AUTOSAR XML (schema 4-3-0)
package /CAN5/ISignalGroup
  11 x i signal group:
    CAN5_SG_FD_BCM1: i-signal=[CAN5_AllDoorSW, CAN5_AntiTheftSeatFold, CAN5_AntitheftSta, CAN5_BCM_Buzzer_Req, CAN5_BCM_DoorLock_Sta, CAN5_BrakeLamp, CAN5_CTDCtrl, CAN5_CTDLockSW, CAN5_CTDUnlockSW, CAN5_CrashDetd, CAN5_Dimmer, CAN5_DimmerEN, CAN5_DoorLockIND, CAN5_DrDoorSW, CAN5_Fr_ChargingDoorCtrl, CAN5_Fr_FogLamp, CAN5_Fr_Wiper_H, CAN5_Fr_Wiper_L, CAN5_H_Beam, CAN5_HazardSW, CAN5_HoodSW, CAN5_HornCtrl, CAN5_LBSD, CAN5_LDRL, CAN5_LTurnLP, CAN5_L_APM_WdwEnable, CAN5_L_Beam, CAN5_LockSetting, CAN5_MirrorCtrl, CAN5_MirrorDefog, CAN5_PosLamp, CAN5_PsDoorSW, CAN5_RBSD, CAN5_RDRL, CAN5_RLDoorSW, CAN5_RRDoorSW, CAN5_RTurnLP, CAN5_ReverseLamp, CAN5_RoomLampH, CAN5_RoomLampL, CAN5_Rr_ChargingDoorCtrl, CAN5_Rr_Defog, CAN5_Rr_FogLamp, CAN5_Rr_Wiper, CAN5_TailgateHDSW, CAN5_TailgateRemote, CAN5_Tailgate_SW, CAN5_TrunkRel, CAN5_WasherCtrl, CAN5_WiperFixMode], system-signal-group=CAN5_SG_FD_BCM1
    CAN5_SG_FD_CONN1: i-signal=[CAN5_CCU_AutoLampSts, CAN5_FD_DKC_VehData_Err, CAN5_FD_DKC_VehData_Sta, CAN5_FD_TBOX_DTCData_Err, CAN5_FD_TBOX_DTCData_Sta, CAN5_FD_TBOX_VehData_Err, CAN5_FD_TBOX_VehData_Sta, CAN5_SWC_mode_Sta], system-signal-group=CAN5_SG_FD_CONN1
    CAN5_SG_FD_THCM2: i-signal=[CAN5_ACSubMode, CAN5_APTC_ActFrRiPwr, CAN5_BatLoopActWtFlw, CAN5_CCU_CbnPreACWkSts, CAN5_CCU_CbnPreEstimdTi, CAN5_CCU_CbnPreSts, CAN5_CCU_HiVoltageReq, CAN5_CoolgFanActDuty, CAN5_DeiceModReq, CAN5_FD_Blower_Cmd, CAN5_FD_Comp_Cmd, CAN5_FD_EWP1_Cmd, CAN5_FD_EWP2_Cmd, CAN5_FD_EWP3_Cmd, CAN5_FD_EXV1_Cmd, CAN5_FD_EXV2_Cmd, CAN5_FD_FWV_Cmd, CAN5_FD_FrLeAPTCHeatPwr_Cmd, CAN5_FD_FrRiAPTCHeatPwr_Cmd, CAN5_FD_FrWPTCHeatPwr_Cmd, CAN5_FD_RrAPTCHeatPwr_Cmd, CAN5_FD_SOTXV_Cmd, CAN5_FD_SOV1_Cmd, CAN5_FD_SOV2_Cmd, CAN5_FD_SOV3_Cmd, CAN5_FD_TWV_Cmd], system-signal-group=CAN5_SG_FD_THCM2
    CAN5_SG_FD_VCU0: i-signal=[CAN5_EVCCAplusPwrUpReq, CAN5_FDADC12VDetAvg, CAN5_Fr_TqSource, CAN5_HVRlyOpFail, CAN5_HVTHCMSysAvail, CAN5_LVBattChrgtimeAct, CAN5_LVBattVoltSta, CAN5_LVChrgHoldTAct, CAN5_LVSilentChrgLv, CAN5_LVSilentChrgReq, CAN5_LVSilentChrgSta, CAN5_MCUActDisFail, CAN5_PMMAllowECUSleep, CAN5_PowerDownFault, CAN5_PowerDownState, CAN5_PowerUpFault, CAN5_PowerUpState, CAN5_PwrDownReq, CAN5_PwrStaConstraint, CAN5_PwrStaONTOIVIPopReq, CAN5_PwrStaONTOIVIPopT, CAN5_PwrStaSelect, CAN5_PwrStaTOSta, CAN5_PwrUpReq, CAN5_Rr_TqSource, CAN5_SchedChgTOSta, CAN5_SilentChkAllowSleep, CAN5_SysAllowReadySta, CAN5_SysPwrSta, CAN5_TCountSta, CAN5_TimerAllowSleep, CAN5_VCUBrkSWSta, CAN5_VCUFLDoorSta, CAN5_VCUFRDoorSta, CAN5_VCURLDoorSta, CAN5_VCURRDoorSta, CAN5_VehHVPwrAvail4THCM], system-signal-group=CAN5_SG_FD_VCU0
    CAN5_SG_FD_VCU1: i-signal=[CAN5_MSA_Crl_Sta, CAN5_PwrSta, CAN5_ShiftGearPosn], system-signal-group=CAN5_SG_FD_VCU1
    CAN5_SG_FD_VCU3: i-signal=[CAN5_CS_VCU3_CAN1, CAN5_EquivAccPedalSWSta, CAN5_Fr_EDUActTqValid, CAN5_Fr_EDUAvailBrkRgnTq, CAN5_Fr_EDUAvailBrkRgnTqValid, CAN5_Fr_EDURealARgnTq, CAN5_Fr_EDURealDrvOrBRgnTq, CAN5_Fr_EDURolRgnTqValid, CAN5_Fr_EDUSpd, CAN5_Fr_EDUSpdValid, CAN5_Fr_RgnDecrSta, CAN5_Fr_RgnPermSta, CAN5_PTCS_PermSta, CAN5_RC_VCU3_CAN1, CAN5_RgnAbnorSta, CAN5_Rr_EDUActTqValid, CAN5_Rr_EDUAvailBrkRgnTq, CAN5_Rr_EDUAvailBrkRgnTqValid, CAN5_Rr_EDURealARgnTq, CAN5_Rr_EDURealDrvOrBRgnTq, CAN5_Rr_EDURolRgnTqValid, CAN5_Rr_EDUSpd, CAN5_Rr_EDUSpdValid, CAN5_Rr_RgnDecrSta, CAN5_Rr_RgnPermSta], system-signal-group=CAN5_SG_FD_VCU3
    CAN5_SG_FD_VCU4: i-signal=[CAN5_Eng_AGSCloseSta, CAN5_Eng_ActvDmpDisabSta, CAN5_Eng_CoastDwSta, CAN5_Eng_PwrLockSta, CAN5_VehMalfunLevel], system-signal-group=CAN5_SG_FD_VCU4
    CAN5_SG_FD_VCU5: i-signal=[CAN5_EDriveSysErr_AccPedalErr, CAN5_EDriveSysErr_MCUErr, CAN5_EDriveSysErr_ShifterErr, CAN5_EDriveSysErr_VCUErr, CAN5_HVSysErr_IsolationErr, CAN5_HVSysErr_PackErr, CAN5_HVSysErr_RelayErr, CAN5_LVSysErr_PwrOutpErr, CAN5_LimphomeAct, CAN5_LowSOCWarn, CAN5_PwrStaErr, CAN5_Re_VehThdChkSta], system-signal-group=CAN5_SG_FD_VCU5
    CAN5_SG_TBOX1: i-signal=[CAN5_Antitheft_Zero, CAN5_CbnPreACEnaReq, CAN5_CbnPreReq, CAN5_CbnPreTarT, CAN5_PowerOff_T_Set, CAN5_ReOutsideMirror, CAN5_Re_DoorLock, CAN5_Re_PwrReqTbox, CAN5_Re_Radio, CAN5_Remote_ACTemp, CAN5_Remote_AutoReq, CAN5_Remote_MidAutoReq, CAN5_TBOX_NET_SIG_STR, CAN5_TBOX_Re_DTCData, CAN5_TBOX_Re_VehData, CAN5_TBOX_RemoteOn, CAN5_TBOX_Remote_PW, CAN5_TBOX_TEST_STATUS, CAN5_Uncounting_Req], system-signal-group=CAN5_SG_TBOX1
    CAN5_SG_XNMm_FUSION: i-signal=[CAN5_NM_FUSION_Active_WU, CAN5_NM_FUSION_CSB, CAN5_NM_FUSION_ERROR_State, CAN5_NM_FUSION_Node_ID, CAN5_NM_FUSION_PNI, CAN5_NM_FUSION_Rpt_Msg_Req], system-signal-group=CAN5_SG_XNMm_FUSION
    CAN5_SG_XNMm_TBOX: i-signal=[CAN5_NM_TBOX_Active_WU, CAN5_NM_TBOX_CSB, CAN5_NM_TBOX_ERROR_State, CAN5_NM_TBOX_Node_ID, CAN5_NM_TBOX_PNI, CAN5_NM_TBOX_Rpt_Msg_Req], system-signal-group=CAN5_SG_XNMm_TBOX
package /CAN5/Cluster
  can cluster CAN5: baudrate=500, can-fd-baudrate=2000
    can physical channel CAN5: comm-connectors=ConnCAN5
      frame CAN5_DiagFuncReqFT: id 0x7D0, frame-length=8, can-addressing-mode=STANDARD, can-fd-frame-support=true, can-frame-rx-behavior=CAN-FD, can-frame-tx-behavior=CAN-FD
        n pdu CAN5_DiagFuncReqFT: length=8
      frame CAN5_DiagPhysReqToTBOX: id 0x6D0, frame-length=8, can-addressing-mode=STANDARD, can-fd-frame-support=true, can-frame-rx-behavior=CAN-FD, can-frame-tx-behavior=CAN-FD
        n pdu CAN5_DiagPhysReqToTBOX: length=8
      frame CAN5_DiagRespFromTBOX: id 0x650, frame-length=8, can-addressing-mode=STANDARD, can-fd-frame-support=true, can-frame-rx-behavior=CAN-FD, can-frame-tx-behavior=CAN-FD
        n pdu CAN5_DiagRespFromTBOX: length=8
      frame CAN5_FD_BCM1: id 0x216, frame-length=16, can-addressing-mode=STANDARD, can-fd-frame-support=true, can-frame-rx-behavior=CAN-FD, can-frame-tx-behavior=CAN-FD
        pdu CAN5_FD_BCM1: length=16, minimum-delay=0.0, transmission-mode-true-timing={cyclic-timing=time-period=0.2, event-controlled-timing={number-of-repetitions=0, repetition-period=0.06}}, unused-bit-pattern=0
          mapping CAN5_SG_FD_BCM1: i-signal-group=CAN5_SG_FD_BCM1, start-position=0, transfer-property=TRIGGERED-ON-CHANGE
          signal CAN5_AllDoorSW: start 124, 1 bit, big-endian, i-signal-type=PRIMITIVE, init-value=constant-reference=Init_CAN5_AllDoorSW, base-type=uint8, implementation-data-type=uint8, transfer-property=TRIGGERED-ON-CHANGE
          signal CAN5_AntiTheftSeatFold: start 84, 1 bit, big-endian, i-signal-type=PRIMITIVE, init-value=constant-reference=Init_CAN5_AntiTheftSeatFold, base-type=uint8, implementation-data-type=uint8, transfer-property=TRIGGERED-ON-CHANGE
          signal CAN5_AntitheftSta: start 83, 2 bit, big-endian, i-signal-type=PRIMITIVE, init-value=constant-reference=Init_CAN5_AntitheftSta, base-type=uint8, implementation-data-type=uint8, transfer-property=TRIGGERED-ON-CHANGE
          signal CAN5_BCM_Buzzer_Req: start 64, 1 bit, big-endian, i-signal-type=PRIMITIVE, init-value=constant-reference=Init_CAN5_BCM_Buzzer_Req, base-type=uint8, implementation-data-type=uint8, transfer-property=TRIGGERED-ON-CHANGE
          signal CAN5_BCM_DoorLock_Sta: start 70, 1 bit, big-endian, i-signal-type=PRIMITIVE, init-value=constant-reference=Init_CAN5_BCM_DoorLock_Sta, base-type=uint8, implementation-data-type=uint8, transfer-property=TRIGGERED-ON-CHANGE
          signal CAN5_BrakeLamp: start 90, 1 bit, big-endian, i-signal-type=PRIMITIVE, init-value=constant-reference=Init_CAN5_BrakeLamp, base-type=uint8, implementation-data-type=uint8, transfer-property=TRIGGERED-ON-CHANGE
          signal CAN5_CTDCtrl: start 113, 2 bit, big-endian, i-signal-type=PRIMITIVE, init-value=constant-reference=Init_CAN5_CTDCtrl, base-type=uint8, implementation-data-type=uint8, transfer-property=TRIGGERED-ON-CHANGE
          signal CAN5_CTDLockSW: start 118, 1 bit, big-endian, i-signal-type=PRIMITIVE, init-value=constant-reference=Init_CAN5_CTDLockSW, base-type=uint8, implementation-data-type=uint8, transfer-property=TRIGGERED-ON-CHANGE
          signal CAN5_CTDUnlockSW: start 119, 1 bit, big-endian, i-signal-type=PRIMITIVE, init-value=constant-reference=Init_CAN5_CTDUnlockSW, base-type=uint8, implementation-data-type=uint8, transfer-property=TRIGGERED-ON-CHANGE
          signal CAN5_CrashDetd: start 85, 1 bit, big-endian, i-signal-type=PRIMITIVE, init-value=constant-reference=Init_CAN5_CrashDetd, base-type=uint8, implementation-data-type=uint8, transfer-property=TRIGGERED-ON-CHANGE
          signal CAN5_Dimmer: start 78, 7 bit, big-endian, i-signal-type=PRIMITIVE, init-value=constant-reference=Init_CAN5_Dimmer, base-type=uint8, implementation-data-type=uint8, transfer-property=TRIGGERED-ON-CHANGE
          signal CAN5_DimmerEN: start 69, 1 bit, big-endian, i-signal-type=PRIMITIVE, init-value=constant-reference=Init_CAN5_DimmerEN, base-type=uint8, implementation-data-type=uint8, transfer-property=TRIGGERED-ON-CHANGE
          signal CAN5_DoorLockIND: start 125, 1 bit, big-endian, i-signal-type=PRIMITIVE, init-value=constant-reference=Init_CAN5_DoorLockIND, base-type=uint8, implementation-data-type=uint8, transfer-property=TRIGGERED-ON-CHANGE
          signal CAN5_DrDoorSW: start 120, 1 bit, big-endian, i-signal-type=PRIMITIVE, init-value=constant-reference=Init_CAN5_DrDoorSW, base-type=uint8, implementation-data-type=uint8, transfer-property=TRIGGERED-ON-CHANGE
          signal CAN5_Fr_ChargingDoorCtrl: start 115, 2 bit, big-endian, i-signal-type=PRIMITIVE, init-value=constant-reference=Init_CAN5_Fr_ChargingDoorCtrl, base-type=uint8, implementation-data-type=uint8, transfer-property=TRIGGERED-ON-CHANGE
          signal CAN5_Fr_FogLamp: start 93, 1 bit, big-endian, i-signal-type=PRIMITIVE, init-value=constant-reference=Init_CAN5_Fr_FogLamp, base-type=uint8, implementation-data-type=uint8, transfer-property=TRIGGERED-ON-CHANGE
          signal CAN5_Fr_Wiper_H: start 110, 1 bit, big-endian, i-signal-type=PRIMITIVE, init-value=constant-reference=Init_CAN5_Fr_Wiper_H, base-type=uint8, implementation-data-type=uint8, transfer-property=TRIGGERED-ON-CHANGE
          signal CAN5_Fr_Wiper_L: start 111, 1 bit, big-endian, i-signal-type=PRIMITIVE, init-value=constant-reference=Init_CAN5_Fr_Wiper_L, base-type=uint8, implementation-data-type=uint8, transfer-property=TRIGGERED-ON-CHANGE
          signal CAN5_H_Beam: start 101, 1 bit, big-endian, i-signal-type=PRIMITIVE, init-value=constant-reference=Init_CAN5_H_Beam, base-type=uint8, implementation-data-type=uint8, transfer-property=TRIGGERED-ON-CHANGE
          signal CAN5_HazardSW: start 95, 1 bit, big-endian, i-signal-type=PRIMITIVE, init-value=constant-reference=Init_CAN5_HazardSW, base-type=uint8, implementation-data-type=uint8, transfer-property=TRIGGERED-ON-CHANGE
          signal CAN5_HoodSW: start 126, 1 bit, big-endian, i-signal-type=PRIMITIVE, init-value=constant-reference=Init_CAN5_HoodSW, base-type=uint8, implementation-data-type=uint8, transfer-property=TRIGGERED-ON-CHANGE
          signal CAN5_HornCtrl: start 71, 1 bit, big-endian, i-signal-type=PRIMITIVE, init-value=constant-reference=Init_CAN5_HornCtrl, base-type=uint8, implementation-data-type=uint8, transfer-property=TRIGGERED-ON-CHANGE
          signal CAN5_LBSD: start 91, 1 bit, big-endian, i-signal-type=PRIMITIVE, init-value=constant-reference=Init_CAN5_LBSD, base-type=uint8, implementation-data-type=uint8, transfer-property=TRIGGERED-ON-CHANGE
          signal CAN5_LDRL: start 103, 1 bit, big-endian, i-signal-type=PRIMITIVE, init-value=constant-reference=Init_CAN5_LDRL, base-type=uint8, implementation-data-type=uint8, transfer-property=TRIGGERED-ON-CHANGE
          signal CAN5_LTurnLP: start 80, 1 bit, big-endian, i-signal-type=PRIMITIVE, init-value=constant-reference=Init_CAN5_LTurnLP, base-type=uint8, implementation-data-type=uint8, transfer-property=TRIGGERED-ON-CHANGE
          signal CAN5_L_APM_WdwEnable: start 87, 1 bit, big-endian, i-signal-type=PRIMITIVE, init-value=constant-reference=Init_CAN5_L_APM_WdwEnable, base-type=uint8, implementation-data-type=uint8, transfer-property=TRIGGERED-ON-CHANGE
          signal CAN5_L_Beam: start 100, 1 bit, big-endian, i-signal-type=PRIMITIVE, init-value=constant-reference=Init_CAN5_L_Beam, base-type=uint8, implementation-data-type=uint8, transfer-property=TRIGGERED-ON-CHANGE
          signal CAN5_LockSetting: start 79, 1 bit, big-endian, i-signal-type=PRIMITIVE, init-value=constant-reference=Init_CAN5_LockSetting, base-type=uint8, implementation-data-type=uint8, transfer-property=TRIGGERED-ON-CHANGE
          signal CAN5_MirrorCtrl: start 109, 2 bit, big-endian, i-signal-type=PRIMITIVE, init-value=constant-reference=Init_CAN5_MirrorCtrl, base-type=uint8, implementation-data-type=uint8, transfer-property=TRIGGERED-ON-CHANGE
          signal CAN5_MirrorDefog: start 104, 1 bit, big-endian, i-signal-type=PRIMITIVE, init-value=constant-reference=Init_CAN5_MirrorDefog, base-type=uint8, implementation-data-type=uint8, transfer-property=TRIGGERED-ON-CHANGE
          signal CAN5_PosLamp: start 102, 1 bit, big-endian, i-signal-type=PRIMITIVE, init-value=constant-reference=Init_CAN5_PosLamp, base-type=uint8, implementation-data-type=uint8, transfer-property=TRIGGERED-ON-CHANGE
          signal CAN5_PsDoorSW: start 121, 1 bit, big-endian, i-signal-type=PRIMITIVE, init-value=constant-reference=Init_CAN5_PsDoorSW, base-type=uint8, implementation-data-type=uint8, transfer-property=TRIGGERED-ON-CHANGE
          signal CAN5_RBSD: start 92, 1 bit, big-endian, i-signal-type=PRIMITIVE, init-value=constant-reference=Init_CAN5_RBSD, base-type=uint8, implementation-data-type=uint8, transfer-property=TRIGGERED-ON-CHANGE
          signal CAN5_RDRL: start 88, 1 bit, big-endian, i-signal-type=PRIMITIVE, init-value=constant-reference=Init_CAN5_RDRL, base-type=uint8, implementation-data-type=uint8, transfer-property=TRIGGERED-ON-CHANGE
          signal CAN5_RLDoorSW: start 122, 1 bit, big-endian, i-signal-type=PRIMITIVE, init-value=constant-reference=Init_CAN5_RLDoorSW, base-type=uint8, implementation-data-type=uint8, transfer-property=TRIGGERED-ON-CHANGE
          signal CAN5_RRDoorSW: start 123, 1 bit, big-endian, i-signal-type=PRIMITIVE, init-value=constant-reference=Init_CAN5_RRDoorSW, base-type=uint8, implementation-data-type=uint8, transfer-property=TRIGGERED-ON-CHANGE
          signal CAN5_RTurnLP: start 81, 1 bit, big-endian, i-signal-type=PRIMITIVE, init-value=constant-reference=Init_CAN5_RTurnLP, base-type=uint8, implementation-data-type=uint8, transfer-property=TRIGGERED-ON-CHANGE
          signal CAN5_ReverseLamp: start 89, 1 bit, big-endian, i-signal-type=PRIMITIVE, init-value=constant-reference=Init_CAN5_ReverseLamp, base-type=uint8, implementation-data-type=uint8, transfer-property=TRIGGERED-ON-CHANGE
          signal CAN5_RoomLampH: start 68, 1 bit, big-endian, i-signal-type=PRIMITIVE, init-value=constant-reference=Init_CAN5_RoomLampH, base-type=uint8, implementation-data-type=uint8, transfer-property=TRIGGERED-ON-CHANGE
          signal CAN5_RoomLampL: start 67, 1 bit, big-endian, i-signal-type=PRIMITIVE, init-value=constant-reference=Init_CAN5_RoomLampL, base-type=uint8, implementation-data-type=uint8, transfer-property=TRIGGERED-ON-CHANGE
          signal CAN5_Rr_ChargingDoorCtrl: start 117, 2 bit, big-endian, i-signal-type=PRIMITIVE, init-value=constant-reference=Init_CAN5_Rr_ChargingDoorCtrl, base-type=uint8, implementation-data-type=uint8, transfer-property=TRIGGERED-ON-CHANGE
          signal CAN5_Rr_Defog: start 105, 1 bit, big-endian, i-signal-type=PRIMITIVE, init-value=constant-reference=Init_CAN5_Rr_Defog, base-type=uint8, implementation-data-type=uint8, transfer-property=TRIGGERED-ON-CHANGE
          signal CAN5_Rr_FogLamp: start 94, 1 bit, big-endian, i-signal-type=PRIMITIVE, init-value=constant-reference=Init_CAN5_Rr_FogLamp, base-type=uint8, implementation-data-type=uint8, transfer-property=TRIGGERED-ON-CHANGE
          signal CAN5_Rr_Wiper: start 96, 1 bit, big-endian, i-signal-type=PRIMITIVE, init-value=constant-reference=Init_CAN5_Rr_Wiper, base-type=uint8, implementation-data-type=uint8, transfer-property=TRIGGERED-ON-CHANGE
          signal CAN5_TailgateHDSW: start 107, 1 bit, big-endian, i-signal-type=PRIMITIVE, init-value=constant-reference=Init_CAN5_TailgateHDSW, base-type=uint8, implementation-data-type=uint8, transfer-property=TRIGGERED-ON-CHANGE
          signal CAN5_TailgateRemote: start 66, 2 bit, big-endian, i-signal-type=PRIMITIVE, init-value=constant-reference=Init_CAN5_TailgateRemote, base-type=uint8, implementation-data-type=uint8, transfer-property=TRIGGERED-ON-CHANGE
          signal CAN5_Tailgate_SW: start 127, 1 bit, big-endian, i-signal-type=PRIMITIVE, init-value=constant-reference=Init_CAN5_Tailgate_SW, base-type=uint8, implementation-data-type=uint8, transfer-property=TRIGGERED-ON-CHANGE
          signal CAN5_TrunkRel: start 106, 1 bit, big-endian, i-signal-type=PRIMITIVE, init-value=constant-reference=Init_CAN5_TrunkRel, base-type=uint8, implementation-data-type=uint8, transfer-property=TRIGGERED-ON-CHANGE
          signal CAN5_WasherCtrl: start 99, 2 bit, big-endian, i-signal-type=PRIMITIVE, init-value=constant-reference=Init_CAN5_WasherCtrl, base-type=uint8, implementation-data-type=uint8, transfer-property=TRIGGERED-ON-CHANGE
          signal CAN5_WiperFixMode: start 97, 1 bit, big-endian, i-signal-type=PRIMITIVE, init-value=constant-reference=Init_CAN5_WiperFixMode, base-type=uint8, implementation-data-type=uint8, transfer-property=TRIGGERED-ON-CHANGE
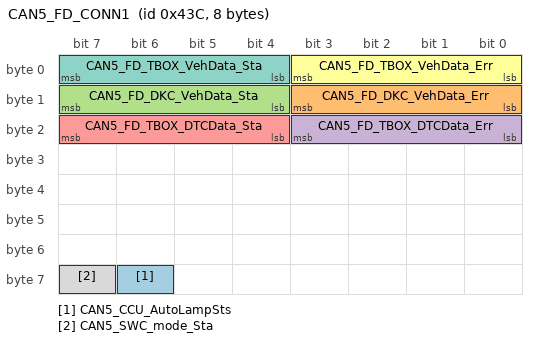
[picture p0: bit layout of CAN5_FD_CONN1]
      frame CAN5_FD_CONN1: id 0x43C, frame-length=8, can-addressing-mode=STANDARD, can-fd-frame-support=true, can-frame-rx-behavior=CAN-FD, can-frame-tx-behavior=CAN-FD
        pdu CAN5_FD_CONN1: length=8, minimum-delay=0.0, transmission-mode-true-timing={cyclic-timing=time-period=0.1, event-controlled-timing={number-of-repetitions=0, repetition-period=0.02}}, unused-bit-pattern=0
          mapping CAN5_SG_FD_CONN1: i-signal-group=CAN5_SG_FD_CONN1, start-position=0, transfer-property=TRIGGERED-ON-CHANGE
          signal CAN5_CCU_AutoLampSts: start 62, 1 bit, big-endian, i-signal-type=PRIMITIVE, init-value=constant-reference=Init_CAN5_CCU_AutoLampSts, base-type=uint8, implementation-data-type=uint8, transfer-property=PENDING
          signal CAN5_FD_DKC_VehData_Err: start 11, 4 bit, big-endian, i-signal-type=PRIMITIVE, init-value=constant-reference=Init_CAN5_FD_DKC_VehData_Err, base-type=uint8, implementation-data-type=uint8, transfer-property=TRIGGERED-ON-CHANGE
          signal CAN5_FD_DKC_VehData_Sta: start 15, 4 bit, big-endian, i-signal-type=PRIMITIVE, init-value=constant-reference=Init_CAN5_FD_DKC_VehData_Sta, base-type=uint8, implementation-data-type=uint8, transfer-property=TRIGGERED-ON-CHANGE
          signal CAN5_FD_TBOX_DTCData_Err: start 19, 4 bit, big-endian, i-signal-type=PRIMITIVE, init-value=constant-reference=Init_CAN5_FD_TBOX_DTCData_Err, base-type=uint8, implementation-data-type=uint8, transfer-property=TRIGGERED-ON-CHANGE
          signal CAN5_FD_TBOX_DTCData_Sta: start 23, 4 bit, big-endian, i-signal-type=PRIMITIVE, init-value=constant-reference=Init_CAN5_FD_TBOX_DTCData_Sta, base-type=uint8, implementation-data-type=uint8, transfer-property=TRIGGERED-ON-CHANGE
          signal CAN5_FD_TBOX_VehData_Err: start 3, 4 bit, big-endian, i-signal-type=PRIMITIVE, init-value=constant-reference=Init_CAN5_FD_TBOX_VehData_Err, base-type=uint8, implementation-data-type=uint8, transfer-property=TRIGGERED-ON-CHANGE
          signal CAN5_FD_TBOX_VehData_Sta: start 7, 4 bit, big-endian, i-signal-type=PRIMITIVE, init-value=constant-reference=Init_CAN5_FD_TBOX_VehData_Sta, base-type=uint8, implementation-data-type=uint8, transfer-property=TRIGGERED-ON-CHANGE
          signal CAN5_SWC_mode_Sta: start 63, 1 bit, big-endian, i-signal-type=PRIMITIVE, init-value=constant-reference=Init_CAN5_SWC_mode_Sta, base-type=uint8, implementation-data-type=uint8, transfer-property=TRIGGERED-ON-CHANGE
      frame CAN5_FD_THCM2: id 0x186, frame-length=20, can-addressing-mode=STANDARD, can-fd-frame-support=true, can-frame-rx-behavior=CAN-FD, can-frame-tx-behavior=CAN-FD
        pdu CAN5_FD_THCM2: length=20, minimum-delay=0.0, transmission-mode-true-timing={cyclic-timing=time-period=0.1, event-controlled-timing={number-of-repetitions=0, repetition-period=0.01}}, unused-bit-pattern=0
          mapping CAN5_SG_FD_THCM2: i-signal-group=CAN5_SG_FD_THCM2, start-position=0, transfer-property=TRIGGERED-ON-CHANGE
          signal CAN5_ACSubMode: start 11, 3 bit, big-endian, i-signal-type=PRIMITIVE, init-value=constant-reference=Init_CAN5_ACSubMode, base-type=uint8, implementation-data-type=uint8, transfer-property=PENDING
          signal CAN5_APTC_ActFrRiPwr: start 143, 8 bit, big-endian, i-signal-type=PRIMITIVE, init-value=constant-reference=Init_CAN5_APTC_ActFrRiPwr, base-type=uint8, implementation-data-type=uint8, transfer-property=TRIGGERED-ON-CHANGE
          signal CAN5_BatLoopActWtFlw: start 151, 8 bit, big-endian, i-signal-type=PRIMITIVE, init-value=constant-reference=Init_CAN5_BatLoopActWtFlw, base-type=uint8, implementation-data-type=uint8, transfer-property=PENDING
          signal CAN5_CCU_CbnPreACWkSts: start 35, 2 bit, big-endian, i-signal-type=PRIMITIVE, init-value=constant-reference=Init_CAN5_CCU_CbnPreACWkSts, base-type=uint8, implementation-data-type=uint8, transfer-property=PENDING
          signal CAN5_CCU_CbnPreEstimdTi: start 55, 6 bit, big-endian, i-signal-type=PRIMITIVE, init-value=constant-reference=Init_CAN5_CCU_CbnPreEstimdTi, base-type=uint8, implementation-data-type=uint8, transfer-property=PENDING
          signal CAN5_CCU_CbnPreSts: start 39, 2 bit, big-endian, i-signal-type=PRIMITIVE, init-value=constant-reference=Init_CAN5_CCU_CbnPreSts, base-type=uint8, implementation-data-type=uint8, transfer-property=PENDING
          signal CAN5_CCU_HiVoltageReq: start 23, 1 bit, big-endian, i-signal-type=PRIMITIVE, init-value=constant-reference=Init_CAN5_CCU_HiVoltageReq, base-type=uint8, implementation-data-type=uint8, transfer-property=PENDING
          signal CAN5_CoolgFanActDuty: start 159, 8 bit, big-endian, i-signal-type=PRIMITIVE, init-value=constant-reference=Init_CAN5_CoolgFanActDuty, base-type=uint8, implementation-data-type=uint8, transfer-property=TRIGGERED-ON-CHANGE
          signal CAN5_DeiceModReq: start 37, 2 bit, big-endian, i-signal-type=PRIMITIVE, init-value=constant-reference=Init_CAN5_DeiceModReq, base-type=uint8, implementation-data-type=uint8, transfer-property=PENDING
          signal CAN5_FD_Blower_Cmd: start 7, 8 bit, big-endian, i-signal-type=PRIMITIVE, init-value=constant-reference=Init_CAN5_FD_Blower_Cmd, base-type=uint8, implementation-data-type=uint8, transfer-property=TRIGGERED-ON-CHANGE
          signal CAN5_FD_Comp_Cmd: start 22, 15 bit, big-endian, i-signal-type=PRIMITIVE, init-value=constant-reference=Init_CAN5_FD_Comp_Cmd, base-type=uint16, implementation-data-type=uint16, transfer-property=TRIGGERED-ON-CHANGE
          signal CAN5_FD_EWP1_Cmd: start 135, 8 bit, big-endian, i-signal-type=PRIMITIVE, init-value=constant-reference=Init_CAN5_FD_EWP1_Cmd, base-type=uint8, implementation-data-type=uint8, transfer-property=PENDING
          signal CAN5_FD_EWP2_Cmd: start 127, 8 bit, big-endian, i-signal-type=PRIMITIVE, init-value=constant-reference=Init_CAN5_FD_EWP2_Cmd, base-type=uint8, implementation-data-type=uint8, transfer-property=PENDING
          signal CAN5_FD_EWP3_Cmd: start 119, 8 bit, big-endian, i-signal-type=PRIMITIVE, init-value=constant-reference=Init_CAN5_FD_EWP3_Cmd, base-type=uint8, implementation-data-type=uint8, transfer-property=PENDING
          signal CAN5_FD_EXV1_Cmd: start 33, 10 bit, big-endian, i-signal-type=PRIMITIVE, init-value=constant-reference=Init_CAN5_FD_EXV1_Cmd, base-type=uint16, implementation-data-type=uint16, transfer-property=PENDING
          signal CAN5_FD_EXV2_Cmd: start 49, 10 bit, big-endian, i-signal-type=PRIMITIVE, init-value=constant-reference=Init_CAN5_FD_EXV2_Cmd, base-type=uint16, implementation-data-type=uint16, transfer-property=PENDING
          signal CAN5_FD_FWV_Cmd: start 8, 1 bit, big-endian, i-signal-type=PRIMITIVE, init-value=constant-reference=Init_CAN5_FD_FWV_Cmd, base-type=uint8, implementation-data-type=uint8, transfer-property=PENDING
          signal CAN5_FD_FrLeAPTCHeatPwr_Cmd: start 87, 8 bit, big-endian, i-signal-type=PRIMITIVE, init-value=constant-reference=Init_CAN5_FD_FrLeAPTCHeatPwr_Cmd, base-type=uint8, implementation-data-type=uint8, transfer-property=TRIGGERED-ON-CHANGE
          signal CAN5_FD_FrRiAPTCHeatPwr_Cmd: start 79, 8 bit, big-endian, i-signal-type=PRIMITIVE, init-value=constant-reference=Init_CAN5_FD_FrRiAPTCHeatPwr_Cmd, base-type=uint8, implementation-data-type=uint8, transfer-property=TRIGGERED-ON-CHANGE
          signal CAN5_FD_FrWPTCHeatPwr_Cmd: start 103, 16 bit, big-endian, i-signal-type=PRIMITIVE, init-value=constant-reference=Init_CAN5_FD_FrWPTCHeatPwr_Cmd, base-type=uint16, implementation-data-type=uint16, transfer-property=TRIGGERED-ON-CHANGE
          signal CAN5_FD_RrAPTCHeatPwr_Cmd: start 95, 8 bit, big-endian, i-signal-type=PRIMITIVE, init-value=constant-reference=Init_CAN5_FD_RrAPTCHeatPwr_Cmd, base-type=uint8, implementation-data-type=uint8, transfer-property=TRIGGERED-ON-CHANGE
          signal CAN5_FD_SOTXV_Cmd: start 12, 1 bit, big-endian, i-signal-type=PRIMITIVE, init-value=constant-reference=Init_CAN5_FD_SOTXV_Cmd, base-type=uint8, implementation-data-type=uint8, transfer-property=PENDING
          signal CAN5_FD_SOV1_Cmd: start 13, 1 bit, big-endian, i-signal-type=PRIMITIVE, init-value=constant-reference=Init_CAN5_FD_SOV1_Cmd, base-type=uint8, implementation-data-type=uint8, transfer-property=PENDING
          signal CAN5_FD_SOV2_Cmd: start 14, 1 bit, big-endian, i-signal-type=PRIMITIVE, init-value=constant-reference=Init_CAN5_FD_SOV2_Cmd, base-type=uint8, implementation-data-type=uint8, transfer-property=PENDING
          signal CAN5_FD_SOV3_Cmd: start 15, 1 bit, big-endian, i-signal-type=PRIMITIVE, init-value=constant-reference=Init_CAN5_FD_SOV3_Cmd, base-type=uint8, implementation-data-type=uint8, transfer-property=PENDING
          signal CAN5_FD_TWV_Cmd: start 71, 8 bit, big-endian, i-signal-type=PRIMITIVE, init-value=constant-reference=Init_CAN5_FD_TWV_Cmd, base-type=uint8, implementation-data-type=uint8, transfer-property=PENDING
      frame CAN5_FD_VCU0: id 0x1F0, frame-length=16, can-addressing-mode=STANDARD, can-fd-frame-support=true, can-frame-rx-behavior=CAN-FD, can-frame-tx-behavior=CAN-FD
        pdu CAN5_FD_VCU0: length=16, minimum-delay=0.0, transmission-mode-true-timing={cyclic-timing=time-period=0.1, event-controlled-timing={number-of-repetitions=0, repetition-period=0.002}}, unused-bit-pattern=0
          mapping CAN5_SG_FD_VCU0: i-signal-group=CAN5_SG_FD_VCU0, start-position=0, transfer-property=TRIGGERED-ON-CHANGE
          signal CAN5_EVCCAplusPwrUpReq: start 94, 1 bit, big-endian, i-signal-type=PRIMITIVE, init-value=constant-reference=Init_CAN5_EVCCAplusPwrUpReq, base-type=uint8, implementation-data-type=uint8, transfer-property=TRIGGERED-ON-CHANGE
          signal CAN5_FDADC12VDetAvg: start 127, 8 bit, big-endian, i-signal-type=PRIMITIVE, init-value=constant-reference=Init_CAN5_FDADC12VDetAvg, base-type=uint8, implementation-data-type=uint8, transfer-property=TRIGGERED-ON-CHANGE
          signal CAN5_Fr_TqSource: start 47, 4 bit, big-endian, i-signal-type=PRIMITIVE, init-value=constant-reference=Init_CAN5_Fr_TqSource, base-type=uint8, implementation-data-type=uint8, transfer-property=TRIGGERED-ON-CHANGE
          signal CAN5_HVRlyOpFail: start 56, 1 bit, big-endian, i-signal-type=PRIMITIVE, init-value=constant-reference=Init_CAN5_HVRlyOpFail, base-type=uint8, implementation-data-type=uint8, transfer-property=TRIGGERED-ON-CHANGE
          signal CAN5_HVTHCMSysAvail: start 41, 2 bit, big-endian, i-signal-type=PRIMITIVE, init-value=constant-reference=Init_CAN5_HVTHCMSysAvail, base-type=uint8, implementation-data-type=uint8, transfer-property=TRIGGERED-ON-CHANGE
          signal CAN5_LVBattChrgtimeAct: start 107, 12 bit, big-endian, i-signal-type=PRIMITIVE, init-value=constant-reference=Init_CAN5_LVBattChrgtimeAct, base-type=uint16, implementation-data-type=uint16, transfer-property=TRIGGERED-ON-CHANGE
          signal CAN5_LVBattVoltSta: start 43, 2 bit, big-endian, i-signal-type=PRIMITIVE, init-value=constant-reference=Init_CAN5_LVBattVoltSta, base-type=uint8, implementation-data-type=uint8, transfer-property=TRIGGERED-ON-CHANGE
          signal CAN5_LVChrgHoldTAct: start 91, 12 bit, big-endian, i-signal-type=PRIMITIVE, init-value=constant-reference=Init_CAN5_LVChrgHoldTAct, base-type=uint16, implementation-data-type=uint16, transfer-property=TRIGGERED-ON-CHANGE
          signal CAN5_LVSilentChrgLv: start 83, 2 bit, big-endian, i-signal-type=PRIMITIVE, init-value=constant-reference=Init_CAN5_LVSilentChrgLv, base-type=uint8, implementation-data-type=uint8, transfer-property=TRIGGERED-ON-CHANGE
          signal CAN5_LVSilentChrgReq: start 81, 1 bit, big-endian, i-signal-type=PRIMITIVE, init-value=constant-reference=Init_CAN5_LVSilentChrgReq, base-type=uint8, implementation-data-type=uint8, transfer-property=TRIGGERED-ON-CHANGE
          signal CAN5_LVSilentChrgSta: start 85, 2 bit, big-endian, i-signal-type=PRIMITIVE, init-value=constant-reference=Init_CAN5_LVSilentChrgSta, base-type=uint8, implementation-data-type=uint8, transfer-property=TRIGGERED-ON-CHANGE
          signal CAN5_MCUActDisFail: start 71, 1 bit, big-endian, i-signal-type=PRIMITIVE, init-value=constant-reference=Init_CAN5_MCUActDisFail, base-type=uint8, implementation-data-type=uint8, transfer-property=TRIGGERED-ON-CHANGE
          signal CAN5_PMMAllowECUSleep: start 95, 1 bit, big-endian, i-signal-type=PRIMITIVE, init-value=constant-reference=Init_CAN5_PMMAllowECUSleep, base-type=uint8, implementation-data-type=uint8, transfer-property=TRIGGERED-ON-CHANGE
          signal CAN5_PowerDownFault: start 19, 4 bit, big-endian, i-signal-type=PRIMITIVE, init-value=constant-reference=Init_CAN5_PowerDownFault, base-type=uint8, implementation-data-type=uint8, transfer-property=TRIGGERED-ON-CHANGE
          signal CAN5_PowerDownState: start 22, 3 bit, big-endian, i-signal-type=PRIMITIVE, init-value=constant-reference=Init_CAN5_PowerDownState, base-type=uint8, implementation-data-type=uint8, transfer-property=TRIGGERED-ON-CHANGE
          signal CAN5_PowerUpFault: start 11, 4 bit, big-endian, i-signal-type=PRIMITIVE, init-value=constant-reference=Init_CAN5_PowerUpFault, base-type=uint8, implementation-data-type=uint8, transfer-property=TRIGGERED-ON-CHANGE
          signal CAN5_PowerUpState: start 15, 4 bit, big-endian, i-signal-type=PRIMITIVE, init-value=constant-reference=Init_CAN5_PowerUpState, base-type=uint8, implementation-data-type=uint8, transfer-property=TRIGGERED-ON-CHANGE
          signal CAN5_PwrDownReq: start 37, 2 bit, big-endian, i-signal-type=PRIMITIVE, init-value=constant-reference=Init_CAN5_PwrDownReq, base-type=uint8, implementation-data-type=uint8, transfer-property=TRIGGERED-ON-CHANGE
          signal CAN5_PwrStaConstraint: start 29, 3 bit, big-endian, i-signal-type=PRIMITIVE, init-value=constant-reference=Init_CAN5_PwrStaConstraint, base-type=uint8, implementation-data-type=uint8, transfer-property=TRIGGERED-ON-CHANGE
          signal CAN5_PwrStaONTOIVIPopReq: start 70, 1 bit, big-endian, i-signal-type=PRIMITIVE, init-value=constant-reference=Init_CAN5_PwrStaONTOIVIPopReq, base-type=uint8, implementation-data-type=uint8, transfer-property=TRIGGERED-ON-CHANGE
          signal CAN5_PwrStaONTOIVIPopT: start 67, 12 bit, big-endian, i-signal-type=PRIMITIVE, init-value=constant-reference=Init_CAN5_PwrStaONTOIVIPopT, base-type=uint16, implementation-data-type=uint16, transfer-property=TRIGGERED-ON-CHANGE
          signal CAN5_PwrStaSelect: start 31, 2 bit, big-endian, i-signal-type=PRIMITIVE, init-value=constant-reference=Init_CAN5_PwrStaSelect, base-type=uint8, implementation-data-type=uint8, transfer-property=TRIGGERED-ON-CHANGE
          signal CAN5_PwrStaTOSta: start 69, 1 bit, big-endian, i-signal-type=PRIMITIVE, init-value=constant-reference=Init_CAN5_PwrStaTOSta, base-type=uint8, implementation-data-type=uint8, transfer-property=TRIGGERED-ON-CHANGE
          signal CAN5_PwrUpReq: start 39, 2 bit, big-endian, i-signal-type=PRIMITIVE, init-value=constant-reference=Init_CAN5_PwrUpReq, base-type=uint8, implementation-data-type=uint8, transfer-property=TRIGGERED-ON-CHANGE
          signal CAN5_Rr_TqSource: start 35, 4 bit, big-endian, i-signal-type=PRIMITIVE, init-value=constant-reference=Init_CAN5_Rr_TqSource, base-type=uint8, implementation-data-type=uint8, transfer-property=TRIGGERED-ON-CHANGE
          signal CAN5_SchedChgTOSta: start 87, 1 bit, big-endian, i-signal-type=PRIMITIVE, init-value=constant-reference=Init_CAN5_SchedChgTOSta, base-type=uint8, implementation-data-type=uint8, transfer-property=TRIGGERED-ON-CHANGE
          signal CAN5_SilentChkAllowSleep: start 86, 1 bit, big-endian, i-signal-type=PRIMITIVE, init-value=constant-reference=Init_CAN5_SilentChkAllowSleep, base-type=uint8, implementation-data-type=uint8, transfer-property=TRIGGERED-ON-CHANGE
          signal CAN5_SysAllowReadySta: start 57, 1 bit, big-endian, i-signal-type=PRIMITIVE, init-value=constant-reference=Init_CAN5_SysAllowReadySta, base-type=uint8, implementation-data-type=uint8, transfer-property=TRIGGERED-ON-CHANGE
          signal CAN5_SysPwrSta: start 7, 4 bit, big-endian, i-signal-type=PRIMITIVE, init-value=constant-reference=Init_CAN5_SysPwrSta, base-type=uint8, implementation-data-type=uint8, transfer-property=TRIGGERED-ON-CHANGE
          signal CAN5_TCountSta: start 26, 2 bit, big-endian, i-signal-type=PRIMITIVE, init-value=constant-reference=Init_CAN5_TCountSta, base-type=uint8, implementation-data-type=uint8, transfer-property=TRIGGERED-ON-CHANGE
          signal CAN5_TimerAllowSleep: start 80, 1 bit, big-endian, i-signal-type=PRIMITIVE, init-value=constant-reference=Init_CAN5_TimerAllowSleep, base-type=uint8, implementation-data-type=uint8, transfer-property=TRIGGERED-ON-CHANGE
          signal CAN5_VCUBrkSWSta: start 63, 2 bit, big-endian, i-signal-type=PRIMITIVE, init-value=constant-reference=Init_CAN5_VCUBrkSWSta, base-type=uint8, implementation-data-type=uint8, transfer-property=TRIGGERED-ON-CHANGE
          signal CAN5_VCUFLDoorSta: start 61, 1 bit, big-endian, i-signal-type=PRIMITIVE, init-value=constant-reference=Init_CAN5_VCUFLDoorSta, base-type=uint8, implementation-data-type=uint8, transfer-property=TRIGGERED-ON-CHANGE
          signal CAN5_VCUFRDoorSta: start 60, 1 bit, big-endian, i-signal-type=PRIMITIVE, init-value=constant-reference=Init_CAN5_VCUFRDoorSta, base-type=uint8, implementation-data-type=uint8, transfer-property=TRIGGERED-ON-CHANGE
          signal CAN5_VCURLDoorSta: start 59, 1 bit, big-endian, i-signal-type=PRIMITIVE, init-value=constant-reference=Init_CAN5_VCURLDoorSta, base-type=uint8, implementation-data-type=uint8, transfer-property=TRIGGERED-ON-CHANGE
          signal CAN5_VCURRDoorSta: start 58, 1 bit, big-endian, i-signal-type=PRIMITIVE, init-value=constant-reference=Init_CAN5_VCURRDoorSta, base-type=uint8, implementation-data-type=uint8, transfer-property=TRIGGERED-ON-CHANGE
          signal CAN5_VehHVPwrAvail4THCM: start 55, 8 bit, big-endian, i-signal-type=PRIMITIVE, init-value=constant-reference=Init_CAN5_VehHVPwrAvail4THCM, base-type=uint8, implementation-data-type=uint8, transfer-property=TRIGGERED-ON-CHANGE
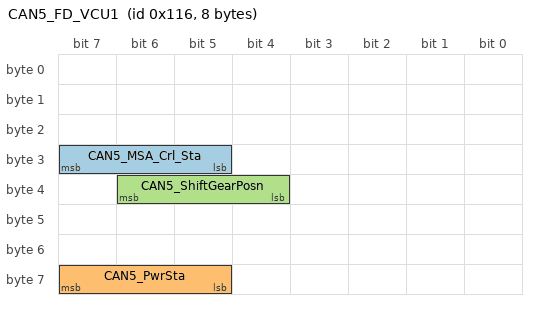
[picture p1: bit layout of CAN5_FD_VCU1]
      frame CAN5_FD_VCU1: id 0x116, frame-length=8, can-addressing-mode=STANDARD, can-fd-frame-support=true, can-frame-rx-behavior=CAN-FD, can-frame-tx-behavior=CAN-FD
        pdu CAN5_FD_VCU1: length=8, minimum-delay=0.0, transmission-mode-true-timing={cyclic-timing=time-period=0.1, event-controlled-timing={number-of-repetitions=0, repetition-period=0.01}}, unused-bit-pattern=0
          mapping CAN5_SG_FD_VCU1: i-signal-group=CAN5_SG_FD_VCU1, start-position=0, transfer-property=TRIGGERED-ON-CHANGE
          signal CAN5_MSA_Crl_Sta: start 31, 3 bit, big-endian, i-signal-type=PRIMITIVE, init-value=constant-reference=Init_CAN5_MSA_Crl_Sta, base-type=uint8, implementation-data-type=uint8, transfer-property=TRIGGERED-ON-CHANGE
          signal CAN5_PwrSta: start 63, 3 bit, big-endian, i-signal-type=PRIMITIVE, init-value=constant-reference=Init_CAN5_PwrSta, base-type=uint8, implementation-data-type=uint8, transfer-property=TRIGGERED-ON-CHANGE
          signal CAN5_ShiftGearPosn: start 38, 3 bit, big-endian, i-signal-type=PRIMITIVE, init-value=constant-reference=Init_CAN5_ShiftGearPosn, base-type=uint8, implementation-data-type=uint8, transfer-property=TRIGGERED-ON-CHANGE
      frame CAN5_FD_VCU3: id 0x159, frame-length=20, can-addressing-mode=STANDARD, can-fd-frame-support=true, can-frame-rx-behavior=CAN-FD, can-frame-tx-behavior=CAN-FD
        pdu CAN5_FD_VCU3: length=20, minimum-delay=0.0, transmission-mode-true-timing=cyclic-timing=time-period=0.01, unused-bit-pattern=0
          mapping CAN5_SG_FD_VCU3: i-signal-group=CAN5_SG_FD_VCU3, start-position=0, transfer-property=PENDING
          signal CAN5_CS_VCU3_CAN1: start 7, 8 bit, big-endian, i-signal-type=PRIMITIVE, init-value=constant-reference=Init_CAN5_CS_VCU3_CAN1, base-type=uint8, implementation-data-type=uint8, transfer-property=PENDING
          signal CAN5_EquivAccPedalSWSta: start 38, 1 bit, big-endian, i-signal-type=PRIMITIVE, init-value=constant-reference=Init_CAN5_EquivAccPedalSWSta, base-type=uint8, implementation-data-type=uint8, transfer-property=PENDING
          signal CAN5_Fr_EDUActTqValid: start 100, 1 bit, big-endian, i-signal-type=PRIMITIVE, init-value=constant-reference=Init_CAN5_Fr_EDUActTqValid, base-type=uint8, implementation-data-type=uint8, transfer-property=PENDING
          signal CAN5_Fr_EDUAvailBrkRgnTq: start 135, 16 bit, big-endian, i-signal-type=PRIMITIVE, init-value=constant-reference=Init_CAN5_Fr_EDUAvailBrkRgnTq, base-type=uint16, implementation-data-type=uint16, transfer-property=PENDING
          signal CAN5_Fr_EDUAvailBrkRgnTqValid: start 102, 1 bit, big-endian, i-signal-type=PRIMITIVE, init-value=constant-reference=Init_CAN5_Fr_EDUAvailBrkRgnTqValid, base-type=uint8, implementation-data-type=uint8, transfer-property=PENDING
          signal CAN5_Fr_EDURealARgnTq: start 119, 16 bit, big-endian, i-signal-type=PRIMITIVE, init-value=constant-reference=Init_CAN5_Fr_EDURealARgnTq, base-type=uint16, implementation-data-type=uint16, transfer-property=PENDING
          signal CAN5_Fr_EDURealDrvOrBRgnTq: start 151, 16 bit, big-endian, i-signal-type=PRIMITIVE, init-value=constant-reference=Init_CAN5_Fr_EDURealDrvOrBRgnTq, base-type=uint16, implementation-data-type=uint16, transfer-property=PENDING
          signal CAN5_Fr_EDURolRgnTqValid: start 36, 1 bit, big-endian, i-signal-type=PRIMITIVE, init-value=constant-reference=Init_CAN5_Fr_EDURolRgnTqValid, base-type=uint8, implementation-data-type=uint8, transfer-property=PENDING
          signal CAN5_Fr_EDUSpd: start 99, 12 bit, big-endian, i-signal-type=PRIMITIVE, init-value=constant-reference=Init_CAN5_Fr_EDUSpd, base-type=uint16, implementation-data-type=uint16, transfer-property=PENDING
          signal CAN5_Fr_EDUSpdValid: start 30, 1 bit, big-endian, i-signal-type=PRIMITIVE, init-value=constant-reference=Init_CAN5_Fr_EDUSpdValid, base-type=uint8, implementation-data-type=uint8, transfer-property=PENDING
          signal CAN5_Fr_RgnDecrSta: start 27, 1 bit, big-endian, i-signal-type=PRIMITIVE, init-value=constant-reference=Init_CAN5_Fr_RgnDecrSta, base-type=uint8, implementation-data-type=uint8, transfer-property=PENDING
          signal CAN5_Fr_RgnPermSta: start 25, 1 bit, big-endian, i-signal-type=PRIMITIVE, init-value=constant-reference=Init_CAN5_Fr_RgnPermSta, base-type=uint8, implementation-data-type=uint8, transfer-property=PENDING
          signal CAN5_PTCS_PermSta: start 39, 1 bit, big-endian, i-signal-type=PRIMITIVE, init-value=constant-reference=Init_CAN5_PTCS_PermSta, base-type=uint8, implementation-data-type=uint8, transfer-property=PENDING
          signal CAN5_RC_VCU3_CAN1: start 15, 4 bit, big-endian, i-signal-type=PRIMITIVE, init-value=constant-reference=Init_CAN5_RC_VCU3_CAN1, base-type=uint8, implementation-data-type=uint8, transfer-property=PENDING
          signal CAN5_RgnAbnorSta: start 28, 1 bit, big-endian, i-signal-type=PRIMITIVE, init-value=constant-reference=Init_CAN5_RgnAbnorSta, base-type=uint8, implementation-data-type=uint8, transfer-property=PENDING
          signal CAN5_Rr_EDUActTqValid: start 101, 1 bit, big-endian, i-signal-type=PRIMITIVE, init-value=constant-reference=Init_CAN5_Rr_EDUActTqValid, base-type=uint8, implementation-data-type=uint8, transfer-property=PENDING
          signal CAN5_Rr_EDUAvailBrkRgnTq: start 71, 16 bit, big-endian, i-signal-type=PRIMITIVE, init-value=constant-reference=Init_CAN5_Rr_EDUAvailBrkRgnTq, base-type=uint16, implementation-data-type=uint16, transfer-property=PENDING
          signal CAN5_Rr_EDUAvailBrkRgnTqValid: start 103, 1 bit, big-endian, i-signal-type=PRIMITIVE, init-value=constant-reference=Init_CAN5_Rr_EDUAvailBrkRgnTqValid, base-type=uint8, implementation-data-type=uint8, transfer-property=PENDING
          signal CAN5_Rr_EDURealARgnTq: start 55, 16 bit, big-endian, i-signal-type=PRIMITIVE, init-value=constant-reference=Init_CAN5_Rr_EDURealARgnTq, base-type=uint16, implementation-data-type=uint16, transfer-property=PENDING
          signal CAN5_Rr_EDURealDrvOrBRgnTq: start 87, 16 bit, big-endian, i-signal-type=PRIMITIVE, init-value=constant-reference=Init_CAN5_Rr_EDURealDrvOrBRgnTq, base-type=uint16, implementation-data-type=uint16, transfer-property=PENDING
          signal CAN5_Rr_EDURolRgnTqValid: start 37, 1 bit, big-endian, i-signal-type=PRIMITIVE, init-value=constant-reference=Init_CAN5_Rr_EDURolRgnTqValid, base-type=uint8, implementation-data-type=uint8, transfer-property=PENDING
          signal CAN5_Rr_EDUSpd: start 35, 12 bit, big-endian, i-signal-type=PRIMITIVE, init-value=constant-reference=Init_CAN5_Rr_EDUSpd, base-type=uint16, implementation-data-type=uint16, transfer-property=PENDING
          signal CAN5_Rr_EDUSpdValid: start 29, 1 bit, big-endian, i-signal-type=PRIMITIVE, init-value=constant-reference=Init_CAN5_Rr_EDUSpdValid, base-type=uint8, implementation-data-type=uint8, transfer-property=PENDING
          signal CAN5_Rr_RgnDecrSta: start 26, 1 bit, big-endian, i-signal-type=PRIMITIVE, init-value=constant-reference=Init_CAN5_Rr_RgnDecrSta, base-type=uint8, implementation-data-type=uint8, transfer-property=PENDING
          signal CAN5_Rr_RgnPermSta: start 24, 1 bit, big-endian, i-signal-type=PRIMITIVE, init-value=constant-reference=Init_CAN5_Rr_RgnPermSta, base-type=uint8, implementation-data-type=uint8, transfer-property=PENDING
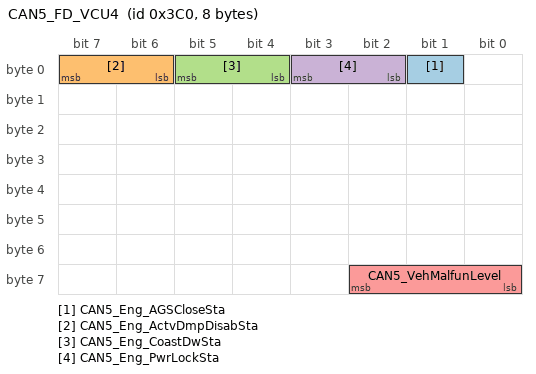
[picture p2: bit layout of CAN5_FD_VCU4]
      frame CAN5_FD_VCU4: id 0x3C0, frame-length=8, can-addressing-mode=STANDARD, can-fd-frame-support=true, can-frame-rx-behavior=CAN-FD, can-frame-tx-behavior=CAN-FD
        pdu CAN5_FD_VCU4: length=8, minimum-delay=0.0, transmission-mode-true-timing={cyclic-timing=time-period=0.2, event-controlled-timing={number-of-repetitions=0, repetition-period=0.05}}, unused-bit-pattern=0
          mapping CAN5_SG_FD_VCU4: i-signal-group=CAN5_SG_FD_VCU4, start-position=0, transfer-property=TRIGGERED-ON-CHANGE
          signal CAN5_Eng_AGSCloseSta: start 1, 1 bit, big-endian, i-signal-type=PRIMITIVE, init-value=constant-reference=Init_CAN5_Eng_AGSCloseSta, base-type=uint8, implementation-data-type=uint8, transfer-property=TRIGGERED-ON-CHANGE
          signal CAN5_Eng_ActvDmpDisabSta: start 7, 2 bit, big-endian, i-signal-type=PRIMITIVE, init-value=constant-reference=Init_CAN5_Eng_ActvDmpDisabSta, base-type=uint8, implementation-data-type=uint8, transfer-property=TRIGGERED-ON-CHANGE
          signal CAN5_Eng_CoastDwSta: start 5, 2 bit, big-endian, i-signal-type=PRIMITIVE, init-value=constant-reference=Init_CAN5_Eng_CoastDwSta, base-type=uint8, implementation-data-type=uint8, transfer-property=TRIGGERED-ON-CHANGE
          signal CAN5_Eng_PwrLockSta: start 3, 2 bit, big-endian, i-signal-type=PRIMITIVE, init-value=constant-reference=Init_CAN5_Eng_PwrLockSta, base-type=uint8, implementation-data-type=uint8, transfer-property=TRIGGERED-ON-CHANGE
          signal CAN5_VehMalfunLevel: start 58, 3 bit, big-endian, i-signal-type=PRIMITIVE, init-value=constant-reference=Init_CAN5_VehMalfunLevel, base-type=uint8, implementation-data-type=uint8, transfer-property=TRIGGERED-ON-CHANGE
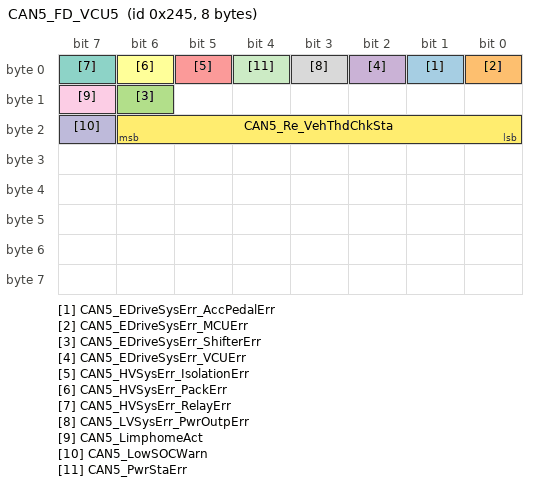
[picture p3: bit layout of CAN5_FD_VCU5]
      frame CAN5_FD_VCU5: id 0x245, frame-length=8, can-addressing-mode=STANDARD, can-fd-frame-support=true, can-frame-rx-behavior=CAN-FD, can-frame-tx-behavior=CAN-FD
        pdu CAN5_FD_VCU5: length=8, minimum-delay=0.0, transmission-mode-true-timing=cyclic-timing=time-period=0.5, unused-bit-pattern=0
          mapping CAN5_SG_FD_VCU5: i-signal-group=CAN5_SG_FD_VCU5, start-position=0, transfer-property=PENDING
          signal CAN5_EDriveSysErr_AccPedalErr: start 1, 1 bit, big-endian, i-signal-type=PRIMITIVE, init-value=constant-reference=Init_CAN5_EDriveSysErr_AccPedalErr, base-type=uint8, implementation-data-type=uint8, transfer-property=PENDING
          signal CAN5_EDriveSysErr_MCUErr: start 0, 1 bit, big-endian, i-signal-type=PRIMITIVE, init-value=constant-reference=Init_CAN5_EDriveSysErr_MCUErr, base-type=uint8, implementation-data-type=uint8, transfer-property=PENDING
          signal CAN5_EDriveSysErr_ShifterErr: start 14, 1 bit, big-endian, i-signal-type=PRIMITIVE, init-value=constant-reference=Init_CAN5_EDriveSysErr_ShifterErr, base-type=uint8, implementation-data-type=uint8, transfer-property=PENDING
          signal CAN5_EDriveSysErr_VCUErr: start 2, 1 bit, big-endian, i-signal-type=PRIMITIVE, init-value=constant-reference=Init_CAN5_EDriveSysErr_VCUErr, base-type=uint8, implementation-data-type=uint8, transfer-property=PENDING
          signal CAN5_HVSysErr_IsolationErr: start 5, 1 bit, big-endian, i-signal-type=PRIMITIVE, init-value=constant-reference=Init_CAN5_HVSysErr_IsolationErr, base-type=uint8, implementation-data-type=uint8, transfer-property=PENDING
          signal CAN5_HVSysErr_PackErr: start 6, 1 bit, big-endian, i-signal-type=PRIMITIVE, init-value=constant-reference=Init_CAN5_HVSysErr_PackErr, base-type=uint8, implementation-data-type=uint8, transfer-property=PENDING
          signal CAN5_HVSysErr_RelayErr: start 7, 1 bit, big-endian, i-signal-type=PRIMITIVE, init-value=constant-reference=Init_CAN5_HVSysErr_RelayErr, base-type=uint8, implementation-data-type=uint8, transfer-property=PENDING
          signal CAN5_LVSysErr_PwrOutpErr: start 3, 1 bit, big-endian, i-signal-type=PRIMITIVE, init-value=constant-reference=Init_CAN5_LVSysErr_PwrOutpErr, base-type=uint8, implementation-data-type=uint8, transfer-property=PENDING
          signal CAN5_LimphomeAct: start 15, 1 bit, big-endian, i-signal-type=PRIMITIVE, init-value=constant-reference=Init_CAN5_LimphomeAct, base-type=uint8, implementation-data-type=uint8, transfer-property=PENDING
          signal CAN5_LowSOCWarn: start 23, 1 bit, big-endian, i-signal-type=PRIMITIVE, init-value=constant-reference=Init_CAN5_LowSOCWarn, base-type=uint8, implementation-data-type=uint8, transfer-property=PENDING
          signal CAN5_PwrStaErr: start 4, 1 bit, big-endian, i-signal-type=PRIMITIVE, init-value=constant-reference=Init_CAN5_PwrStaErr, base-type=uint8, implementation-data-type=uint8, transfer-property=PENDING
          signal CAN5_Re_VehThdChkSta: start 22, 7 bit, big-endian, i-signal-type=PRIMITIVE, init-value=constant-reference=Init_CAN5_Re_VehThdChkSta, base-type=uint8, implementation-data-type=uint8, transfer-property=PENDING
      frame CAN5_TBOX1: id 0x442, frame-length=12, can-addressing-mode=STANDARD, can-fd-frame-support=true, can-frame-rx-behavior=CAN-FD, can-frame-tx-behavior=CAN-FD
        pdu CAN5_TBOX1: length=12, minimum-delay=0.0, transmission-mode-true-timing=cyclic-timing=time-period=0.2, unused-bit-pattern=0
          mapping CAN5_SG_TBOX1: i-signal-group=CAN5_SG_TBOX1, start-position=0, transfer-property=PENDING
          signal CAN5_Antitheft_Zero: start 23, 4 bit, big-endian, i-signal-type=PRIMITIVE, init-value=constant-reference=Init_CAN5_Antitheft_Zero, base-type=uint8, implementation-data-type=uint8, transfer-property=PENDING
          signal CAN5_CbnPreACEnaReq: start 47, 2 bit, big-endian, i-signal-type=PRIMITIVE, init-value=constant-reference=Init_CAN5_CbnPreACEnaReq, base-type=uint8, implementation-data-type=uint8, transfer-property=PENDING
          signal CAN5_CbnPreReq: start 45, 2 bit, big-endian, i-signal-type=PRIMITIVE, init-value=constant-reference=Init_CAN5_CbnPreReq, base-type=uint8, implementation-data-type=uint8, transfer-property=PENDING
          signal CAN5_CbnPreTarT: start 37, 6 bit, big-endian, i-signal-type=PRIMITIVE, init-value=constant-reference=Init_CAN5_CbnPreTarT, base-type=uint8, implementation-data-type=uint8, transfer-property=PENDING
          signal CAN5_PowerOff_T_Set: start 70, 7 bit, big-endian, i-signal-type=PRIMITIVE, init-value=constant-reference=Init_CAN5_PowerOff_T_Set, base-type=uint8, implementation-data-type=uint8, transfer-property=PENDING
          signal CAN5_ReOutsideMirror: start 43, 2 bit, big-endian, i-signal-type=PRIMITIVE, init-value=constant-reference=Init_CAN5_ReOutsideMirror, base-type=uint8, implementation-data-type=uint8, transfer-property=PENDING
          signal CAN5_Re_DoorLock: start 7, 16 bit, big-endian, i-signal-type=PRIMITIVE, init-value=constant-reference=Init_CAN5_Re_DoorLock, base-type=uint16, implementation-data-type=uint16, transfer-property=PENDING
          signal CAN5_Re_PwrReqTbox: start 31, 3 bit, big-endian, i-signal-type=PRIMITIVE, init-value=constant-reference=Init_CAN5_Re_PwrReqTbox, base-type=uint8, implementation-data-type=uint8, transfer-property=PENDING
          signal CAN5_Re_Radio: start 60, 1 bit, big-endian, i-signal-type=PRIMITIVE, init-value=constant-reference=Init_CAN5_Re_Radio, base-type=uint8, implementation-data-type=uint8, transfer-property=PENDING
          signal CAN5_Remote_ACTemp: start 77, 6 bit, big-endian, i-signal-type=PRIMITIVE, init-value=constant-reference=Init_CAN5_Remote_ACTemp, base-type=uint8, implementation-data-type=uint8, transfer-property=PENDING
          signal CAN5_Remote_AutoReq: start 79, 1 bit, big-endian, i-signal-type=PRIMITIVE, init-value=constant-reference=Init_CAN5_Remote_AutoReq, base-type=uint8, implementation-data-type=uint8, transfer-property=PENDING
          signal CAN5_Remote_MidAutoReq: start 78, 1 bit, big-endian, i-signal-type=PRIMITIVE, init-value=constant-reference=Init_CAN5_Remote_MidAutoReq, base-type=uint8, implementation-data-type=uint8, transfer-property=PENDING
          signal CAN5_TBOX_NET_SIG_STR: start 55, 4 bit, big-endian, i-signal-type=PRIMITIVE, init-value=constant-reference=Init_CAN5_TBOX_NET_SIG_STR, base-type=uint8, implementation-data-type=uint8, transfer-property=PENDING
          signal CAN5_TBOX_Re_DTCData: start 41, 2 bit, big-endian, i-signal-type=PRIMITIVE, init-value=constant-reference=Init_CAN5_TBOX_Re_DTCData, base-type=uint8, implementation-data-type=uint8, transfer-property=PENDING
          signal CAN5_TBOX_Re_VehData: start 19, 2 bit, big-endian, i-signal-type=PRIMITIVE, init-value=constant-reference=Init_CAN5_TBOX_Re_VehData, base-type=uint8, implementation-data-type=uint8, transfer-property=PENDING
          signal CAN5_TBOX_RemoteOn: start 17, 2 bit, big-endian, i-signal-type=PRIMITIVE, init-value=constant-reference=Init_CAN5_TBOX_RemoteOn, base-type=uint8, implementation-data-type=uint8, transfer-property=PENDING
          signal CAN5_TBOX_Remote_PW: start 28, 5 bit, big-endian, i-signal-type=PRIMITIVE, init-value=constant-reference=Init_CAN5_TBOX_Remote_PW, base-type=uint8, implementation-data-type=uint8, transfer-property=PENDING
          signal CAN5_TBOX_TEST_STATUS: start 51, 4 bit, big-endian, i-signal-type=PRIMITIVE, init-value=constant-reference=Init_CAN5_TBOX_TEST_STATUS, base-type=uint8, implementation-data-type=uint8, transfer-property=PENDING
          signal CAN5_Uncounting_Req: start 39, 2 bit, big-endian, i-signal-type=PRIMITIVE, init-value=constant-reference=Init_CAN5_Uncounting_Req, base-type=uint8, implementation-data-type=uint8, transfer-property=PENDING
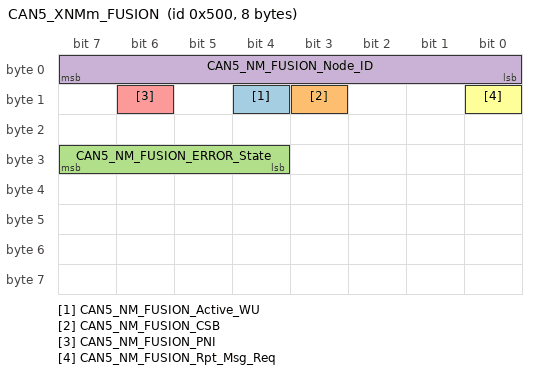
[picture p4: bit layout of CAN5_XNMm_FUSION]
      frame CAN5_XNMm_FUSION: id 0x500, frame-length=8, can-addressing-mode=STANDARD, can-fd-frame-support=false, can-frame-rx-behavior=CAN-20, can-frame-tx-behavior=CAN-20
        pdu CAN5_XNMm_FUSION: length=8, minimum-delay=0.0, transmission-mode-true-timing=cyclic-timing=time-period=0.7, unused-bit-pattern=0
          mapping CAN5_SG_XNMm_FUSION: i-signal-group=CAN5_SG_XNMm_FUSION, start-position=0, transfer-property=PENDING
          signal CAN5_NM_FUSION_Active_WU: start 12, 1 bit, big-endian, i-signal-type=PRIMITIVE, init-value=constant-reference=Init_CAN5_NM_FUSION_Active_WU, base-type=uint8, implementation-data-type=uint8, transfer-property=PENDING
          signal CAN5_NM_FUSION_CSB: start 11, 1 bit, big-endian, i-signal-type=PRIMITIVE, init-value=constant-reference=Init_CAN5_NM_FUSION_CSB, base-type=uint8, implementation-data-type=uint8, transfer-property=PENDING
          signal CAN5_NM_FUSION_ERROR_State: start 31, 4 bit, big-endian, i-signal-type=PRIMITIVE, init-value=constant-reference=Init_CAN5_NM_FUSION_ERROR_State, base-type=uint8, implementation-data-type=uint8, transfer-property=PENDING
          signal CAN5_NM_FUSION_Node_ID: start 7, 8 bit, big-endian, i-signal-type=PRIMITIVE, init-value=constant-reference=Init_CAN5_NM_FUSION_Node_ID, base-type=uint8, implementation-data-type=uint8, transfer-property=PENDING
          signal CAN5_NM_FUSION_PNI: start 14, 1 bit, big-endian, i-signal-type=PRIMITIVE, init-value=constant-reference=Init_CAN5_NM_FUSION_PNI, base-type=uint8, implementation-data-type=uint8, transfer-property=PENDING
          signal CAN5_NM_FUSION_Rpt_Msg_Req: start 8, 1 bit, big-endian, i-signal-type=PRIMITIVE, init-value=constant-reference=Init_CAN5_NM_FUSION_Rpt_Msg_Req, base-type=uint8, implementation-data-type=uint8, transfer-property=PENDING
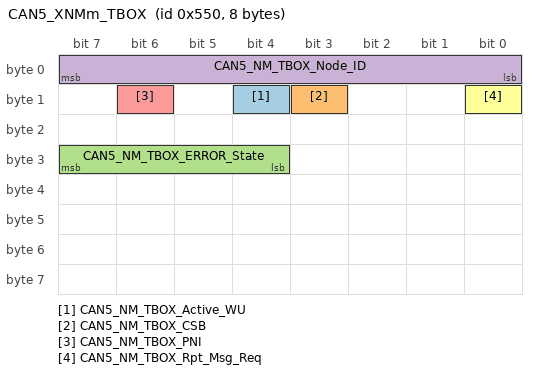
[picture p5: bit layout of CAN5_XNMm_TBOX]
      frame CAN5_XNMm_TBOX: id 0x550, frame-length=8, can-addressing-mode=STANDARD, can-fd-frame-support=false, can-frame-rx-behavior=CAN-20, can-frame-tx-behavior=CAN-20
        pdu CAN5_XNMm_TBOX: length=8, minimum-delay=0.0, transmission-mode-true-timing=cyclic-timing=time-period=0.7, unused-bit-pattern=0
          mapping CAN5_SG_XNMm_TBOX: i-signal-group=CAN5_SG_XNMm_TBOX, start-position=0, transfer-property=PENDING
          signal CAN5_NM_TBOX_Active_WU: start 12, 1 bit, big-endian, i-signal-type=PRIMITIVE, init-value=constant-reference=Init_CAN5_NM_TBOX_Active_WU, base-type=uint8, implementation-data-type=uint8, transfer-property=PENDING
          signal CAN5_NM_TBOX_CSB: start 11, 1 bit, big-endian, i-signal-type=PRIMITIVE, init-value=constant-reference=Init_CAN5_NM_TBOX_CSB, base-type=uint8, implementation-data-type=uint8, transfer-property=PENDING
          signal CAN5_NM_TBOX_ERROR_State: start 31, 4 bit, big-endian, i-signal-type=PRIMITIVE, init-value=constant-reference=Init_CAN5_NM_TBOX_ERROR_State, base-type=uint8, implementation-data-type=uint8, transfer-property=PENDING
          signal CAN5_NM_TBOX_Node_ID: start 7, 8 bit, big-endian, i-signal-type=PRIMITIVE, init-value=constant-reference=Init_CAN5_NM_TBOX_Node_ID, base-type=uint8, implementation-data-type=uint8, transfer-property=PENDING
          signal CAN5_NM_TBOX_PNI: start 14, 1 bit, big-endian, i-signal-type=PRIMITIVE, init-value=constant-reference=Init_CAN5_NM_TBOX_PNI, base-type=uint8, implementation-data-type=uint8, transfer-property=PENDING
          signal CAN5_NM_TBOX_Rpt_Msg_Req: start 8, 1 bit, big-endian, i-signal-type=PRIMITIVE, init-value=constant-reference=Init_CAN5_NM_TBOX_Rpt_Msg_Req, base-type=uint8, implementation-data-type=uint8, transfer-property=PENDING
package /CAN5/ConstantSpecification
  208 x constant specification:
    Init_CAN5_AllDoorSW: value-spec=0
    Init_CAN5_AntiTheftSeatFold: value-spec=0
    Init_CAN5_AntitheftSta: value-spec=0
    Init_CAN5_BCM_Buzzer_Req: value-spec=0
    Init_CAN5_BCM_DoorLock_Sta: value-spec=0
    Init_CAN5_BrakeLamp: value-spec=0
    Init_CAN5_CTDCtrl: value-spec=0
    Init_CAN5_CTDLockSW: value-spec=0
    Init_CAN5_CTDUnlockSW: value-spec=0
    Init_CAN5_CrashDetd: value-spec=0
    Init_CAN5_Dimmer: value-spec=0
    Init_CAN5_DimmerEN: value-spec=0
    Init_CAN5_DoorLockIND: value-spec=0
    Init_CAN5_DrDoorSW: value-spec=0
    Init_CAN5_Fr_ChargingDoorCtrl: value-spec=0
    Init_CAN5_Fr_FogLamp: value-spec=0
    Init_CAN5_Fr_Wiper_H: value-spec=0
    Init_CAN5_Fr_Wiper_L: value-spec=0
    Init_CAN5_H_Beam: value-spec=0
    Init_CAN5_HazardSW: value-spec=0
    Init_CAN5_HoodSW: value-spec=0
    Init_CAN5_HornCtrl: value-spec=0
    Init_CAN5_LBSD: value-spec=0
    Init_CAN5_LDRL: value-spec=0
    Init_CAN5_LTurnLP: value-spec=0
    Init_CAN5_L_APM_WdwEnable: value-spec=0
    Init_CAN5_L_Beam: value-spec=0
    Init_CAN5_LockSetting: value-spec=0
    Init_CAN5_MirrorCtrl: value-spec=0
    Init_CAN5_MirrorDefog: value-spec=0
    Init_CAN5_PosLamp: value-spec=0
    Init_CAN5_PsDoorSW: value-spec=0
    Init_CAN5_RBSD: value-spec=0
    Init_CAN5_RDRL: value-spec=0
    Init_CAN5_RLDoorSW: value-spec=0
    Init_CAN5_RRDoorSW: value-spec=0
    Init_CAN5_RTurnLP: value-spec=0
    Init_CAN5_ReverseLamp: value-spec=0
    Init_CAN5_RoomLampH: value-spec=0
    Init_CAN5_RoomLampL: value-spec=0
    Init_CAN5_Rr_ChargingDoorCtrl: value-spec=0
    Init_CAN5_Rr_Defog: value-spec=0
    Init_CAN5_Rr_FogLamp: value-spec=0
    Init_CAN5_Rr_Wiper: value-spec=0
    Init_CAN5_TailgateHDSW: value-spec=0
    Init_CAN5_TailgateRemote: value-spec=0
    Init_CAN5_Tailgate_SW: value-spec=0
    Init_CAN5_TrunkRel: value-spec=0
    Init_CAN5_WasherCtrl: value-spec=0
    Init_CAN5_WiperFixMode: value-spec=0
    Init_CAN5_SG_FD_BCM1: value-spec=fields=[Init_CAN5_AllDoorSW, Init_CAN5_AntiTheftSeatFold, Init_CAN5_AntitheftSta, Init_CAN5_BCM_Buzzer_Req, Init_CAN5_BCM_DoorLock_Sta, Init_CAN5_BrakeLamp, Init_CAN5_CTDCtrl, Init_CAN5_CTDLockSW, Init_CAN5_CTDUnlockSW, Init_CAN5_CrashDetd, Init_CAN5_Dimmer, Init_CAN5_DimmerEN, Init_CAN5_DoorLockIND, Init_CAN5_DrDoorSW, Init_CAN5_Fr_ChargingDoorCtrl, Init_CAN5_Fr_FogLamp, Init_CAN5_Fr_Wiper_H, Init_CAN5_Fr_Wiper_L, Init_CAN5_H_Beam, Init_CAN5_HazardSW, Init_CAN5_HoodSW, Init_CAN5_HornCtrl, Init_CAN5_LBSD, Init_CAN5_LDRL, Init_CAN5_LTurnLP, Init_CAN5_L_APM_WdwEnable, Init_CAN5_L_Beam, Init_CAN5_LockSetting, Init_CAN5_MirrorCtrl, Init_CAN5_MirrorDefog, Init_CAN5_PosLamp, Init_CAN5_PsDoorSW, Init_CAN5_RBSD, Init_CAN5_RDRL, Init_CAN5_RLDoorSW, Init_CAN5_RRDoorSW, Init_CAN5_RTurnLP, Init_CAN5_ReverseLamp, Init_CAN5_RoomLampH, Init_CAN5_RoomLampL, Init_CAN5_Rr_ChargingDoorCtrl, Init_CAN5_Rr_Defog, Init_CAN5_Rr_FogLamp, Init_CAN5_Rr_Wiper, Init_CAN5_TailgateHDSW, Init_CAN5_TailgateRemote, Init_CAN5_Tailgate_SW, Init_CAN5_TrunkRel, Init_CAN5_WasherCtrl, Init_CAN5_WiperFixMode]
    Init_CAN5_CCU_AutoLampSts: value-spec=0
    Init_CAN5_FD_DKC_VehData_Err: value-spec=0
    Init_CAN5_FD_DKC_VehData_Sta: value-spec=0
    Init_CAN5_FD_TBOX_DTCData_Err: value-spec=0
    Init_CAN5_FD_TBOX_DTCData_Sta: value-spec=0
    Init_CAN5_FD_TBOX_VehData_Err: value-spec=0
    Init_CAN5_FD_TBOX_VehData_Sta: value-spec=0
    Init_CAN5_SWC_mode_Sta: value-spec=0
    Init_CAN5_SG_FD_CONN1: value-spec=fields=[Init_CAN5_CCU_AutoLampSts, Init_CAN5_FD_DKC_VehData_Err, Init_CAN5_FD_DKC_VehData_Sta, Init_CAN5_FD_TBOX_DTCData_Err, Init_CAN5_FD_TBOX_DTCData_Sta, Init_CAN5_FD_TBOX_VehData_Err, Init_CAN5_FD_TBOX_VehData_Sta, Init_CAN5_SWC_mode_Sta]
    Init_CAN5_ACSubMode: value-spec=0
    Init_CAN5_APTC_ActFrRiPwr: value-spec=0
    Init_CAN5_BatLoopActWtFlw: value-spec=0
    Init_CAN5_CCU_CbnPreACWkSts: value-spec=0
    Init_CAN5_CCU_CbnPreEstimdTi: value-spec=0
    Init_CAN5_CCU_CbnPreSts: value-spec=0
    Init_CAN5_CCU_HiVoltageReq: value-spec=0
    Init_CAN5_CoolgFanActDuty: value-spec=0
    Init_CAN5_DeiceModReq: value-spec=0
    Init_CAN5_FD_Blower_Cmd: value-spec=0
    Init_CAN5_FD_Comp_Cmd: value-spec=0
    Init_CAN5_FD_EWP{1..3}_Cmd: value-spec=0
    Init_CAN5_FD_EXV1_Cmd: value-spec=0
    Init_CAN5_FD_EXV2_Cmd: value-spec=0
    Init_CAN5_FD_FWV_Cmd: value-spec=0
    Init_CAN5_FD_FrLeAPTCHeatPwr_Cmd: value-spec=0
    Init_CAN5_FD_FrRiAPTCHeatPwr_Cmd: value-spec=0
    Init_CAN5_FD_FrWPTCHeatPwr_Cmd: value-spec=0
    Init_CAN5_FD_RrAPTCHeatPwr_Cmd: value-spec=0
    Init_CAN5_FD_SOTXV_Cmd: value-spec=0
    Init_CAN5_FD_SOV{1..3}_Cmd: value-spec=0
    Init_CAN5_FD_TWV_Cmd: value-spec=0
    Init_CAN5_SG_FD_THCM2: value-spec=fields=[Init_CAN5_ACSubMode, Init_CAN5_APTC_ActFrRiPwr, Init_CAN5_BatLoopActWtFlw, Init_CAN5_CCU_CbnPreACWkSts, Init_CAN5_CCU_CbnPreEstimdTi, Init_CAN5_CCU_CbnPreSts, Init_CAN5_CCU_HiVoltageReq, Init_CAN5_CoolgFanActDuty, Init_CAN5_DeiceModReq, Init_CAN5_FD_Blower_Cmd, Init_CAN5_FD_Comp_Cmd, Init_CAN5_FD_EWP1_Cmd, Init_CAN5_FD_EWP2_Cmd, Init_CAN5_FD_EWP3_Cmd, Init_CAN5_FD_EXV1_Cmd, Init_CAN5_FD_EXV2_Cmd, Init_CAN5_FD_FWV_Cmd, Init_CAN5_FD_FrLeAPTCHeatPwr_Cmd, Init_CAN5_FD_FrRiAPTCHeatPwr_Cmd, Init_CAN5_FD_FrWPTCHeatPwr_Cmd, Init_CAN5_FD_RrAPTCHeatPwr_Cmd, Init_CAN5_FD_SOTXV_Cmd, Init_CAN5_FD_SOV1_Cmd, Init_CAN5_FD_SOV2_Cmd, Init_CAN5_FD_SOV3_Cmd, Init_CAN5_FD_TWV_Cmd]
    Init_CAN5_EVCCAplusPwrUpReq: value-spec=0
    Init_CAN5_FDADC12VDetAvg: value-spec=0
    Init_CAN5_Fr_TqSource: value-spec=0
    Init_CAN5_HVRlyOpFail: value-spec=0
    Init_CAN5_HVTHCMSysAvail: value-spec=0
    Init_CAN5_LVBattChrgtimeAct: value-spec=0
    Init_CAN5_LVBattVoltSta: value-spec=0
    Init_CAN5_LVChrgHoldTAct: value-spec=0
    Init_CAN5_LVSilentChrgLv: value-spec=0
    Init_CAN5_LVSilentChrgReq: value-spec=0
    Init_CAN5_LVSilentChrgSta: value-spec=0
    Init_CAN5_MCUActDisFail: value-spec=0
    Init_CAN5_PMMAllowECUSleep: value-spec=0
    Init_CAN5_PowerDownFault: value-spec=0
    Init_CAN5_PowerDownState: value-spec=0
    Init_CAN5_PowerUpFault: value-spec=0
    Init_CAN5_PowerUpState: value-spec=0
    Init_CAN5_PwrDownReq: value-spec=0
    Init_CAN5_PwrStaConstraint: value-spec=0
    Init_CAN5_PwrStaONTOIVIPopReq: value-spec=0
    Init_CAN5_PwrStaONTOIVIPopT: value-spec=0
    Init_CAN5_PwrStaSelect: value-spec=0
    Init_CAN5_PwrStaTOSta: value-spec=0
    Init_CAN5_PwrUpReq: value-spec=0
    Init_CAN5_Rr_TqSource: value-spec=0
    Init_CAN5_SchedChgTOSta: value-spec=0
    Init_CAN5_SilentChkAllowSleep: value-spec=0
    Init_CAN5_SysAllowReadySta: value-spec=0
    Init_CAN5_SysPwrSta: value-spec=0
    Init_CAN5_TCountSta: value-spec=0
    Init_CAN5_TimerAllowSleep: value-spec=0
    Init_CAN5_VCUBrkSWSta: value-spec=0
    Init_CAN5_VCUFLDoorSta: value-spec=0
    Init_CAN5_VCUFRDoorSta: value-spec=0
    Init_CAN5_VCURLDoorSta: value-spec=0
    Init_CAN5_VCURRDoorSta: value-spec=0
    Init_CAN5_VehHVPwrAvail4THCM: value-spec=0
    Init_CAN5_SG_FD_VCU0: value-spec=fields=[Init_CAN5_EVCCAplusPwrUpReq, Init_CAN5_FDADC12VDetAvg, Init_CAN5_Fr_TqSource, Init_CAN5_HVRlyOpFail, Init_CAN5_HVTHCMSysAvail, Init_CAN5_LVBattChrgtimeAct, Init_CAN5_LVBattVoltSta, Init_CAN5_LVChrgHoldTAct, Init_CAN5_LVSilentChrgLv, Init_CAN5_LVSilentChrgReq, Init_CAN5_LVSilentChrgSta, Init_CAN5_MCUActDisFail, Init_CAN5_PMMAllowECUSleep, Init_CAN5_PowerDownFault, Init_CAN5_PowerDownState, Init_CAN5_PowerUpFault, Init_CAN5_PowerUpState, Init_CAN5_PwrDownReq, Init_CAN5_PwrStaConstraint, Init_CAN5_PwrStaONTOIVIPopReq, Init_CAN5_PwrStaONTOIVIPopT, Init_CAN5_PwrStaSelect, Init_CAN5_PwrStaTOSta, Init_CAN5_PwrUpReq, Init_CAN5_Rr_TqSource, Init_CAN5_SchedChgTOSta, Init_CAN5_SilentChkAllowSleep, Init_CAN5_SysAllowReadySta, Init_CAN5_SysPwrSta, Init_CAN5_TCountSta, Init_CAN5_TimerAllowSleep, Init_CAN5_VCUBrkSWSta, Init_CAN5_VCUFLDoorSta, Init_CAN5_VCUFRDoorSta, Init_CAN5_VCURLDoorSta, Init_CAN5_VCURRDoorSta, Init_CAN5_VehHVPwrAvail4THCM]
    Init_CAN5_MSA_Crl_Sta: value-spec=0
    Init_CAN5_PwrSta: value-spec=0
    Init_CAN5_ShiftGearPosn: value-spec=0
    Init_CAN5_SG_FD_VCU1: value-spec=fields=[Init_CAN5_MSA_Crl_Sta, Init_CAN5_PwrSta, Init_CAN5_ShiftGearPosn]
    Init_CAN5_CS_VCU3_CAN1: value-spec=0
    Init_CAN5_EquivAccPedalSWSta: value-spec=0
    Init_CAN5_Fr_EDUActTqValid: value-spec=0
    Init_CAN5_Fr_EDUAvailBrkRgnTq: value-spec=10600
    Init_CAN5_Fr_EDUAvailBrkRgnTqValid: value-spec=0
    Init_CAN5_Fr_EDURealARgnTq: value-spec=5300
    Init_CAN5_Fr_EDURealDrvOrBRgnTq: value-spec=10600
    Init_CAN5_Fr_EDURolRgnTqValid: value-spec=0
    Init_CAN5_Fr_EDUSpd: value-spec=2000
    Init_CAN5_Fr_EDUSpdValid: value-spec=0
    Init_CAN5_Fr_RgnDecrSta: value-spec=0
    Init_CAN5_Fr_RgnPermSta: value-spec=0
    Init_CAN5_PTCS_PermSta: value-spec=0
    Init_CAN5_RC_VCU3_CAN1: value-spec=0
    Init_CAN5_RgnAbnorSta: value-spec=0
    Init_CAN5_Rr_EDUActTqValid: value-spec=0
    Init_CAN5_Rr_EDUAvailBrkRgnTq: value-spec=10600
    Init_CAN5_Rr_EDUAvailBrkRgnTqValid: value-spec=0
    Init_CAN5_Rr_EDURealARgnTq: value-spec=5300
    Init_CAN5_Rr_EDURealDrvOrBRgnTq: value-spec=10600
    Init_CAN5_Rr_EDURolRgnTqValid: value-spec=0
    Init_CAN5_Rr_EDUSpd: value-spec=2000
    Init_CAN5_Rr_EDUSpdValid: value-spec=0
    Init_CAN5_Rr_RgnDecrSta: value-spec=0
    Init_CAN5_Rr_RgnPermSta: value-spec=0
    Init_CAN5_SG_FD_VCU3: value-spec=fields=[Init_CAN5_CS_VCU3_CAN1, Init_CAN5_EquivAccPedalSWSta, Init_CAN5_Fr_EDUActTqValid, Init_CAN5_Fr_EDUAvailBrkRgnTq, Init_CAN5_Fr_EDUAvailBrkRgnTqValid, Init_CAN5_Fr_EDURealARgnTq, Init_CAN5_Fr_EDURealDrvOrBRgnTq, Init_CAN5_Fr_EDURolRgnTqValid, Init_CAN5_Fr_EDUSpd, Init_CAN5_Fr_EDUSpdValid, Init_CAN5_Fr_RgnDecrSta, Init_CAN5_Fr_RgnPermSta, Init_CAN5_PTCS_PermSta, Init_CAN5_RC_VCU3_CAN1, Init_CAN5_RgnAbnorSta, Init_CAN5_Rr_EDUActTqValid, Init_CAN5_Rr_EDUAvailBrkRgnTq, Init_CAN5_Rr_EDUAvailBrkRgnTqValid, Init_CAN5_Rr_EDURealARgnTq, Init_CAN5_Rr_EDURealDrvOrBRgnTq, Init_CAN5_Rr_EDURolRgnTqValid, Init_CAN5_Rr_EDUSpd, Init_CAN5_Rr_EDUSpdValid, Init_CAN5_Rr_RgnDecrSta, Init_CAN5_Rr_RgnPermSta]
    Init_CAN5_Eng_AGSCloseSta: value-spec=0
    Init_CAN5_Eng_ActvDmpDisabSta: value-spec=0
    Init_CAN5_Eng_CoastDwSta: value-spec=0
    Init_CAN5_Eng_PwrLockSta: value-spec=0
    Init_CAN5_VehMalfunLevel: value-spec=0
    Init_CAN5_SG_FD_VCU4: value-spec=fields=[Init_CAN5_Eng_AGSCloseSta, Init_CAN5_Eng_ActvDmpDisabSta, Init_CAN5_Eng_CoastDwSta, Init_CAN5_Eng_PwrLockSta, Init_CAN5_VehMalfunLevel]
    Init_CAN5_EDriveSysErr_AccPedalErr: value-spec=0
    Init_CAN5_EDriveSysErr_MCUErr: value-spec=0
    Init_CAN5_EDriveSysErr_ShifterErr: value-spec=0
    Init_CAN5_EDriveSysErr_VCUErr: value-spec=0
    Init_CAN5_HVSysErr_IsolationErr: value-spec=0
    Init_CAN5_HVSysErr_PackErr: value-spec=0
    Init_CAN5_HVSysErr_RelayErr: value-spec=0
    Init_CAN5_LVSysErr_PwrOutpErr: value-spec=0
    Init_CAN5_LimphomeAct: value-spec=0
    Init_CAN5_LowSOCWarn: value-spec=0
    Init_CAN5_PwrStaErr: value-spec=0
    Init_CAN5_Re_VehThdChkSta: value-spec=0
    Init_CAN5_SG_FD_VCU5: value-spec=fields=[Init_CAN5_EDriveSysErr_AccPedalErr, Init_CAN5_EDriveSysErr_MCUErr, Init_CAN5_EDriveSysErr_ShifterErr, Init_CAN5_EDriveSysErr_VCUErr, Init_CAN5_HVSysErr_IsolationErr, Init_CAN5_HVSysErr_PackErr, Init_CAN5_HVSysErr_RelayErr, Init_CAN5_LVSysErr_PwrOutpErr, Init_CAN5_LimphomeAct, Init_CAN5_LowSOCWarn, Init_CAN5_PwrStaErr, Init_CAN5_Re_VehThdChkSta]
    Init_CAN5_Antitheft_Zero: value-spec=0
    Init_CAN5_CbnPreACEnaReq: value-spec=0
    Init_CAN5_CbnPreReq: value-spec=0
    Init_CAN5_CbnPreTarT: value-spec=0
    Init_CAN5_PowerOff_T_Set: value-spec=0
    Init_CAN5_ReOutsideMirror: value-spec=0
    Init_CAN5_Re_DoorLock: value-spec=0
    Init_CAN5_Re_PwrReqTbox: value-spec=0
    Init_CAN5_Re_Radio: value-spec=0
    Init_CAN5_Remote_ACTemp: value-spec=0
    Init_CAN5_Remote_AutoReq: value-spec=0
    Init_CAN5_Remote_MidAutoReq: value-spec=0
    Init_CAN5_TBOX_NET_SIG_STR: value-spec=0
    Init_CAN5_TBOX_Re_DTCData: value-spec=0
    Init_CAN5_TBOX_Re_VehData: value-spec=0
    Init_CAN5_TBOX_RemoteOn: value-spec=0
    Init_CAN5_TBOX_Remote_PW: value-spec=0
    Init_CAN5_TBOX_TEST_STATUS: value-spec=0
    Init_CAN5_Uncounting_Req: value-spec=0
    Init_CAN5_SG_TBOX1: value-spec=fields=[Init_CAN5_Antitheft_Zero, Init_CAN5_CbnPreACEnaReq, Init_CAN5_CbnPreReq, Init_CAN5_CbnPreTarT, Init_CAN5_PowerOff_T_Set, Init_CAN5_ReOutsideMirror, Init_CAN5_Re_DoorLock, Init_CAN5_Re_PwrReqTbox, Init_CAN5_Re_Radio, Init_CAN5_Remote_ACTemp, Init_CAN5_Remote_AutoReq, Init_CAN5_Remote_MidAutoReq, Init_CAN5_TBOX_NET_SIG_STR, Init_CAN5_TBOX_Re_DTCData, Init_CAN5_TBOX_Re_VehData, Init_CAN5_TBOX_RemoteOn, Init_CAN5_TBOX_Remote_PW, Init_CAN5_TBOX_TEST_STATUS, Init_CAN5_Uncounting_Req]
    Init_CAN5_NM_FUSION_Active_WU: value-spec=0
    Init_CAN5_NM_FUSION_CSB: value-spec=0
    Init_CAN5_NM_FUSION_ERROR_State: value-spec=0
    Init_CAN5_NM_FUSION_Node_ID: value-spec=0
    Init_CAN5_NM_FUSION_PNI: value-spec=0
    Init_CAN5_NM_FUSION_Rpt_Msg_Req: value-spec=0
    Init_CAN5_SG_XNMm_FUSION: value-spec=fields=[Init_CAN5_NM_FUSION_Active_WU, Init_CAN5_NM_FUSION_CSB, Init_CAN5_NM_FUSION_ERROR_State, Init_CAN5_NM_FUSION_Node_ID, Init_CAN5_NM_FUSION_PNI, Init_CAN5_NM_FUSION_Rpt_Msg_Req]
    Init_CAN5_NM_TBOX_Active_WU: value-spec=0
    Init_CAN5_NM_TBOX_CSB: value-spec=0
    Init_CAN5_NM_TBOX_ERROR_State: value-spec=0
    Init_CAN5_NM_TBOX_Node_ID: value-spec=0
    Init_CAN5_NM_TBOX_PNI: value-spec=0
    Init_CAN5_NM_TBOX_Rpt_Msg_Req: value-spec=0
    Init_CAN5_SG_XNMm_TBOX: value-spec=fields=[Init_CAN5_NM_TBOX_Active_WU, Init_CAN5_NM_TBOX_CSB, Init_CAN5_NM_TBOX_ERROR_State, Init_CAN5_NM_TBOX_Node_ID, Init_CAN5_NM_TBOX_PNI, Init_CAN5_NM_TBOX_Rpt_Msg_Req]
package /CAN5/ImplementationDataTypes
  11 x impl type, all with category=STRUCTURE:
    DT_CAN5_SG_FD_BCM1
      50 x element, all with category=TYPE_REFERENCE, implementation-data-type=uint8:
        CAN5_AllDoorSW
        CAN5_AntiTheftSeatFold
        CAN5_AntitheftSta
        CAN5_BCM_Buzzer_Req
        CAN5_BCM_DoorLock_Sta
        CAN5_BrakeLamp
        CAN5_CTDCtrl
        CAN5_CTDLockSW
        CAN5_CTDUnlockSW
        CAN5_CrashDetd
        CAN5_Dimmer
        CAN5_DimmerEN
        CAN5_DoorLockIND
        CAN5_DrDoorSW
        CAN5_Fr_ChargingDoorCtrl
        CAN5_Fr_FogLamp
        CAN5_Fr_Wiper_H
        CAN5_Fr_Wiper_L
        CAN5_H_Beam
        CAN5_HazardSW
        CAN5_HoodSW
        CAN5_HornCtrl
        CAN5_LBSD
        CAN5_LDRL
        CAN5_LTurnLP
        CAN5_L_APM_WdwEnable
        CAN5_L_Beam
        CAN5_LockSetting
        CAN5_MirrorCtrl
        CAN5_MirrorDefog
        CAN5_PosLamp
        CAN5_PsDoorSW
        CAN5_RBSD
        CAN5_RDRL
        CAN5_RLDoorSW
        CAN5_RRDoorSW
        CAN5_RTurnLP
        CAN5_ReverseLamp
        CAN5_RoomLampH
        CAN5_RoomLampL
        CAN5_Rr_ChargingDoorCtrl
        CAN5_Rr_Defog
        CAN5_Rr_FogLamp
        CAN5_Rr_Wiper
        CAN5_TailgateHDSW
        CAN5_TailgateRemote
        CAN5_Tailgate_SW
        CAN5_TrunkRel
        CAN5_WasherCtrl
        CAN5_WiperFixMode
    DT_CAN5_SG_FD_CONN1
      8 x element, all with category=TYPE_REFERENCE, implementation-data-type=uint8:
        CAN5_CCU_AutoLampSts
        CAN5_FD_DKC_VehData_Err
        CAN5_FD_DKC_VehData_Sta
        CAN5_FD_TBOX_DTCData_Err
        CAN5_FD_TBOX_DTCData_Sta
        CAN5_FD_TBOX_VehData_Err
        CAN5_FD_TBOX_VehData_Sta
        CAN5_SWC_mode_Sta
    DT_CAN5_SG_FD_THCM2
      26 x element, all with category=TYPE_REFERENCE:
        CAN5_ACSubMode: implementation-data-type=uint8
        CAN5_APTC_ActFrRiPwr: implementation-data-type=uint8
        CAN5_BatLoopActWtFlw: implementation-data-type=uint8
        CAN5_CCU_CbnPreACWkSts: implementation-data-type=uint8
        CAN5_CCU_CbnPreEstimdTi: implementation-data-type=uint8
        CAN5_CCU_CbnPreSts: implementation-data-type=uint8
        CAN5_CCU_HiVoltageReq: implementation-data-type=uint8
        CAN5_CoolgFanActDuty: implementation-data-type=uint8
        CAN5_DeiceModReq: implementation-data-type=uint8
        CAN5_FD_Blower_Cmd: implementation-data-type=uint8
        CAN5_FD_Comp_Cmd: implementation-data-type=uint16
        CAN5_FD_EWP{1..3}_Cmd: implementation-data-type=uint8
        CAN5_FD_EXV1_Cmd: implementation-data-type=uint16
        CAN5_FD_EXV2_Cmd: implementation-data-type=uint16
        CAN5_FD_FWV_Cmd: implementation-data-type=uint8
        CAN5_FD_FrLeAPTCHeatPwr_Cmd: implementation-data-type=uint8
        CAN5_FD_FrRiAPTCHeatPwr_Cmd: implementation-data-type=uint8
        CAN5_FD_FrWPTCHeatPwr_Cmd: implementation-data-type=uint16
        CAN5_FD_RrAPTCHeatPwr_Cmd: implementation-data-type=uint8
        CAN5_FD_SOTXV_Cmd: implementation-data-type=uint8
        CAN5_FD_SOV{1..3}_Cmd: implementation-data-type=uint8
        CAN5_FD_TWV_Cmd: implementation-data-type=uint8
    DT_CAN5_SG_FD_VCU0
      37 x element, all with category=TYPE_REFERENCE:
        CAN5_EVCCAplusPwrUpReq: implementation-data-type=uint8
        CAN5_FDADC12VDetAvg: implementation-data-type=uint8
        CAN5_Fr_TqSource: implementation-data-type=uint8
        CAN5_HVRlyOpFail: implementation-data-type=uint8
        CAN5_HVTHCMSysAvail: implementation-data-type=uint8
        CAN5_LVBattChrgtimeAct: implementation-data-type=uint16
        CAN5_LVBattVoltSta: implementation-data-type=uint8
        CAN5_LVChrgHoldTAct: implementation-data-type=uint16
        CAN5_LVSilentChrgLv: implementation-data-type=uint8
        CAN5_LVSilentChrgReq: implementation-data-type=uint8
        CAN5_LVSilentChrgSta: implementation-data-type=uint8
        CAN5_MCUActDisFail: implementation-data-type=uint8
        CAN5_PMMAllowECUSleep: implementation-data-type=uint8
        CAN5_PowerDownFault: implementation-data-type=uint8
        CAN5_PowerDownState: implementation-data-type=uint8
        CAN5_PowerUpFault: implementation-data-type=uint8
        CAN5_PowerUpState: implementation-data-type=uint8
        CAN5_PwrDownReq: implementation-data-type=uint8
        CAN5_PwrStaConstraint: implementation-data-type=uint8
        CAN5_PwrStaONTOIVIPopReq: implementation-data-type=uint8
        CAN5_PwrStaONTOIVIPopT: implementation-data-type=uint16
        CAN5_PwrStaSelect: implementation-data-type=uint8
        CAN5_PwrStaTOSta: implementation-data-type=uint8
        CAN5_PwrUpReq: implementation-data-type=uint8
        CAN5_Rr_TqSource: implementation-data-type=uint8
        CAN5_SchedChgTOSta: implementation-data-type=uint8
        CAN5_SilentChkAllowSleep: implementation-data-type=uint8
        CAN5_SysAllowReadySta: implementation-data-type=uint8
        CAN5_SysPwrSta: implementation-data-type=uint8
        CAN5_TCountSta: implementation-data-type=uint8
        CAN5_TimerAllowSleep: implementation-data-type=uint8
        CAN5_VCUBrkSWSta: implementation-data-type=uint8
        CAN5_VCUFLDoorSta: implementation-data-type=uint8
        CAN5_VCUFRDoorSta: implementation-data-type=uint8
        CAN5_VCURLDoorSta: implementation-data-type=uint8
        CAN5_VCURRDoorSta: implementation-data-type=uint8
        CAN5_VehHVPwrAvail4THCM: implementation-data-type=uint8
    DT_CAN5_SG_FD_VCU1
      element CAN5_MSA_Crl_Sta: implementation-data-type=uint8
      element CAN5_PwrSta: implementation-data-type=uint8
      element CAN5_ShiftGearPosn: implementation-data-type=uint8
    DT_CAN5_SG_FD_VCU3
      25 x element, all with category=TYPE_REFERENCE:
        CAN5_CS_VCU3_CAN1: implementation-data-type=uint8
        CAN5_EquivAccPedalSWSta: implementation-data-type=uint8
        CAN5_Fr_EDUActTqValid: implementation-data-type=uint8
        CAN5_Fr_EDUAvailBrkRgnTq: implementation-data-type=uint16
        CAN5_Fr_EDUAvailBrkRgnTqValid: implementation-data-type=uint8
        CAN5_Fr_EDURealARgnTq: implementation-data-type=uint16
        CAN5_Fr_EDURealDrvOrBRgnTq: implementation-data-type=uint16
        CAN5_Fr_EDURolRgnTqValid: implementation-data-type=uint8
        CAN5_Fr_EDUSpd: implementation-data-type=uint16
        CAN5_Fr_EDUSpdValid: implementation-data-type=uint8
        CAN5_Fr_RgnDecrSta: implementation-data-type=uint8
        CAN5_Fr_RgnPermSta: implementation-data-type=uint8
        CAN5_PTCS_PermSta: implementation-data-type=uint8
        CAN5_RC_VCU3_CAN1: implementation-data-type=uint8
        CAN5_RgnAbnorSta: implementation-data-type=uint8
        CAN5_Rr_EDUActTqValid: implementation-data-type=uint8
        CAN5_Rr_EDUAvailBrkRgnTq: implementation-data-type=uint16
        CAN5_Rr_EDUAvailBrkRgnTqValid: implementation-data-type=uint8
        CAN5_Rr_EDURealARgnTq: implementation-data-type=uint16
        CAN5_Rr_EDURealDrvOrBRgnTq: implementation-data-type=uint16
        CAN5_Rr_EDURolRgnTqValid: implementation-data-type=uint8
        CAN5_Rr_EDUSpd: implementation-data-type=uint16
        CAN5_Rr_EDUSpdValid: implementation-data-type=uint8
        CAN5_Rr_RgnDecrSta: implementation-data-type=uint8
        CAN5_Rr_RgnPermSta: implementation-data-type=uint8
    DT_CAN5_SG_FD_VCU4
      5 x element, all with category=TYPE_REFERENCE, implementation-data-type=uint8:
        CAN5_Eng_AGSCloseSta
        CAN5_Eng_ActvDmpDisabSta
        CAN5_Eng_CoastDwSta
        CAN5_Eng_PwrLockSta
        CAN5_VehMalfunLevel
    DT_CAN5_SG_FD_VCU5
      12 x element, all with category=TYPE_REFERENCE, implementation-data-type=uint8:
        CAN5_EDriveSysErr_AccPedalErr
        CAN5_EDriveSysErr_MCUErr
        CAN5_EDriveSysErr_ShifterErr
        CAN5_EDriveSysErr_VCUErr
        CAN5_HVSysErr_IsolationErr
        CAN5_HVSysErr_PackErr
        CAN5_HVSysErr_RelayErr
        CAN5_LVSysErr_PwrOutpErr
        CAN5_LimphomeAct
        CAN5_LowSOCWarn
        CAN5_PwrStaErr
        CAN5_Re_VehThdChkSta
    DT_CAN5_SG_TBOX1
      19 x element, all with category=TYPE_REFERENCE:
        CAN5_Antitheft_Zero: implementation-data-type=uint8
        CAN5_CbnPreACEnaReq: implementation-data-type=uint8
        CAN5_CbnPreReq: implementation-data-type=uint8
        CAN5_CbnPreTarT: implementation-data-type=uint8
        CAN5_PowerOff_T_Set: implementation-data-type=uint8
        CAN5_ReOutsideMirror: implementation-data-type=uint8
        CAN5_Re_DoorLock: implementation-data-type=uint16
        CAN5_Re_PwrReqTbox: implementation-data-type=uint8
        CAN5_Re_Radio: implementation-data-type=uint8
        CAN5_Remote_ACTemp: implementation-data-type=uint8
        CAN5_Remote_AutoReq: implementation-data-type=uint8
        CAN5_Remote_MidAutoReq: implementation-data-type=uint8
        CAN5_TBOX_NET_SIG_STR: implementation-data-type=uint8
        CAN5_TBOX_Re_DTCData: implementation-data-type=uint8
        CAN5_TBOX_Re_VehData: implementation-data-type=uint8
        CAN5_TBOX_RemoteOn: implementation-data-type=uint8
        CAN5_TBOX_Remote_PW: implementation-data-type=uint8
        CAN5_TBOX_TEST_STATUS: implementation-data-type=uint8
        CAN5_Uncounting_Req: implementation-data-type=uint8
    DT_CAN5_SG_XNMm_FUSION
      6 x element, all with category=TYPE_REFERENCE, implementation-data-type=uint8:
        CAN5_NM_FUSION_Active_WU
        CAN5_NM_FUSION_CSB
        CAN5_NM_FUSION_ERROR_State
        CAN5_NM_FUSION_Node_ID
        CAN5_NM_FUSION_PNI
        CAN5_NM_FUSION_Rpt_Msg_Req
    DT_CAN5_SG_XNMm_TBOX
      6 x element, all with category=TYPE_REFERENCE, implementation-data-type=uint8:
        CAN5_NM_TBOX_Active_WU
        CAN5_NM_TBOX_CSB
        CAN5_NM_TBOX_ERROR_State
        CAN5_NM_TBOX_Node_ID
        CAN5_NM_TBOX_PNI
        CAN5_NM_TBOX_Rpt_Msg_Req
